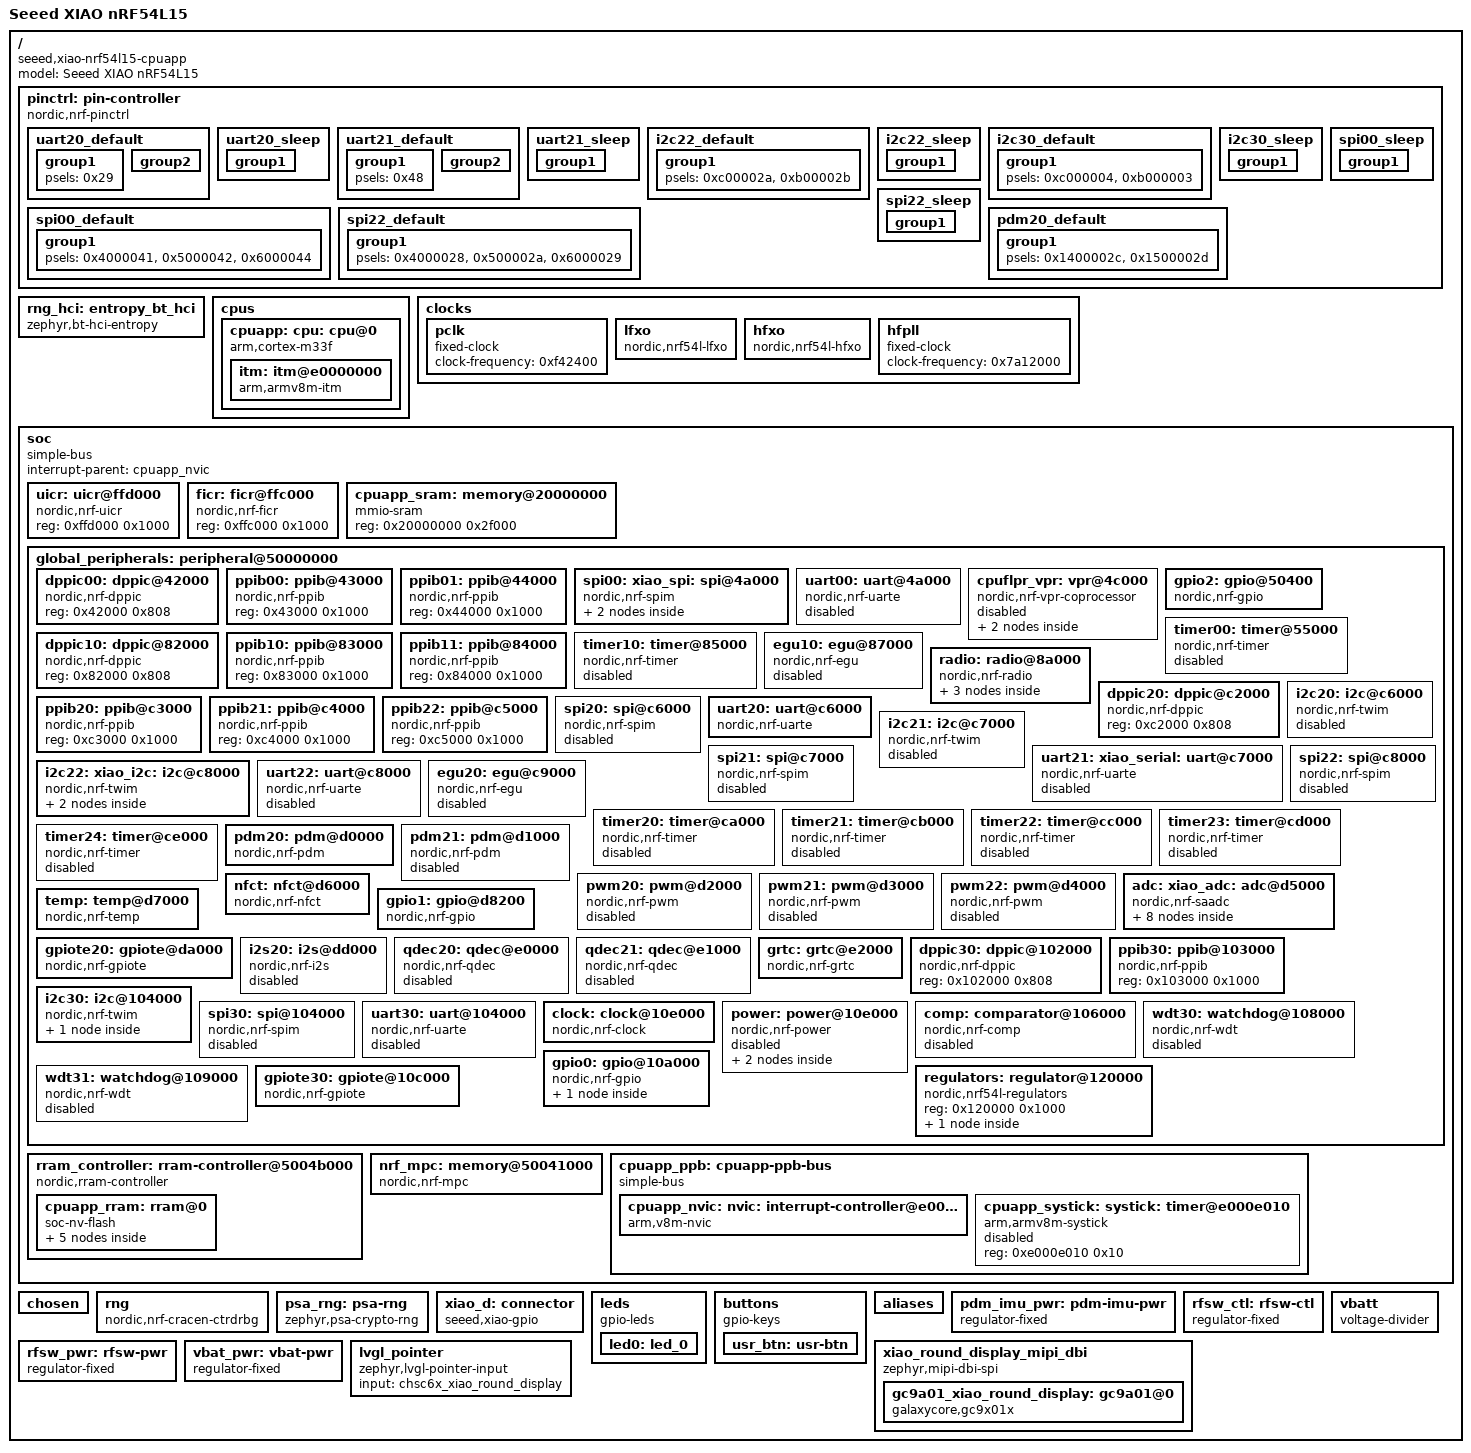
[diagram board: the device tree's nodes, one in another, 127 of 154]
/dts-v1/;

/* node '/' defined in zephyr\dts\vendor\nordic\nrf_common.dtsi:24 */
/ {
	#address-cells = < 0x1 >;                  /* in zephyr\dts\vendor\nordic\nrf54l_05_10_15.dtsi:19 */
	#size-cells = < 0x1 >;                     /* in zephyr\dts\vendor\nordic\nrf54l_05_10_15.dtsi:20 */
	model = "Seeed XIAO nRF54L15";             /* in zephyr\boards\arm\xiao_nrf54l15\xiao_nrf54l15_nrf54l15_cpuapp.dts:11 */
	compatible = "seeed,xiao-nrf54l15-cpuapp"; /* in zephyr\boards\arm\xiao_nrf54l15\xiao_nrf54l15_nrf54l15_cpuapp.dts:12 */

	/* node '/pin-controller' defined in zephyr\dts\vendor\nordic\nrf_common.dtsi:25 */
	pinctrl: pin-controller {
		compatible = "nordic,nrf-pinctrl"; /* in zephyr\dts\vendor\nordic\nrf_common.dtsi:30 */

		/* node '/pin-controller/uart20_default' defined in zephyr\boards\arm\xiao_nrf54l15\xiao_nrf54l15-pinctrl.dtsi:6 */
		uart20_default: uart20_default {
			phandle = < 0x8 >; /* in zephyr\boards\arm\xiao_nrf54l15\xiao_nrf54l15_common.dtsi:39 */

			/* node '/pin-controller/uart20_default/group1' defined in zephyr\boards\arm\xiao_nrf54l15\xiao_nrf54l15-pinctrl.dtsi:7 */
			group1 {
				psels = < 0x29 >; /* in zephyr\boards\arm\xiao_nrf54l15\xiao_nrf54l15-pinctrl.dtsi:8 */
			};

			/* node '/pin-controller/uart20_default/group2' defined in zephyr\boards\arm\xiao_nrf54l15\xiao_nrf54l15-pinctrl.dtsi:11 */
			group2 {
				psels = < 0x1000028 >; /* in zephyr\boards\arm\xiao_nrf54l15\xiao_nrf54l15-pinctrl.dtsi:12 */
				bias-pull-up;          /* in zephyr\boards\arm\xiao_nrf54l15\xiao_nrf54l15-pinctrl.dtsi:13 */
			};
		};

		/* node '/pin-controller/uart20_sleep' defined in zephyr\boards\arm\xiao_nrf54l15\xiao_nrf54l15-pinctrl.dtsi:17 */
		uart20_sleep: uart20_sleep {
			phandle = < 0x9 >; /* in zephyr\boards\arm\xiao_nrf54l15\xiao_nrf54l15_common.dtsi:40 */

			/* node '/pin-controller/uart20_sleep/group1' defined in zephyr\boards\arm\xiao_nrf54l15\xiao_nrf54l15-pinctrl.dtsi:18 */
			group1 {
				psels = < 0x29 >,
				        < 0x1000028 >; /* in zephyr\boards\arm\xiao_nrf54l15\xiao_nrf54l15-pinctrl.dtsi:19 */
				low-power-enable;      /* in zephyr\boards\arm\xiao_nrf54l15\xiao_nrf54l15-pinctrl.dtsi:21 */
			};
		};

		/* node '/pin-controller/uart21_default' defined in zephyr\boards\arm\xiao_nrf54l15\xiao_nrf54l15-pinctrl.dtsi:25 */
		uart21_default: uart21_default {
			phandle = < 0xa >; /* in zephyr\boards\arm\xiao_nrf54l15\xiao_nrf54l15_common.dtsi:46 */

			/* node '/pin-controller/uart21_default/group1' defined in zephyr\boards\arm\xiao_nrf54l15\xiao_nrf54l15-pinctrl.dtsi:26 */
			group1 {
				psels = < 0x48 >; /* in zephyr\boards\arm\xiao_nrf54l15\xiao_nrf54l15-pinctrl.dtsi:27 */
			};

			/* node '/pin-controller/uart21_default/group2' defined in zephyr\boards\arm\xiao_nrf54l15\xiao_nrf54l15-pinctrl.dtsi:30 */
			group2 {
				psels = < 0x1000047 >; /* in zephyr\boards\arm\xiao_nrf54l15\xiao_nrf54l15-pinctrl.dtsi:31 */
				bias-pull-up;          /* in zephyr\boards\arm\xiao_nrf54l15\xiao_nrf54l15-pinctrl.dtsi:32 */
			};
		};

		/* node '/pin-controller/uart21_sleep' defined in zephyr\boards\arm\xiao_nrf54l15\xiao_nrf54l15-pinctrl.dtsi:36 */
		uart21_sleep: uart21_sleep {
			phandle = < 0xb >; /* in zephyr\boards\arm\xiao_nrf54l15\xiao_nrf54l15_common.dtsi:47 */

			/* node '/pin-controller/uart21_sleep/group1' defined in zephyr\boards\arm\xiao_nrf54l15\xiao_nrf54l15-pinctrl.dtsi:37 */
			group1 {
				psels = < 0x48 >,
				        < 0x1000047 >; /* in zephyr\boards\arm\xiao_nrf54l15\xiao_nrf54l15-pinctrl.dtsi:38 */
				low-power-enable;      /* in zephyr\boards\arm\xiao_nrf54l15\xiao_nrf54l15-pinctrl.dtsi:40 */
			};
		};

		/* node '/pin-controller/i2c22_default' defined in zephyr\boards\arm\xiao_nrf54l15\xiao_nrf54l15-pinctrl.dtsi:44 */
		i2c22_default: i2c22_default {
			phandle = < 0xc >; /* in zephyr\boards\arm\xiao_nrf54l15\xiao_nrf54l15_common.dtsi:52 */

			/* node '/pin-controller/i2c22_default/group1' defined in zephyr\boards\arm\xiao_nrf54l15\xiao_nrf54l15-pinctrl.dtsi:45 */
			group1 {
				psels = < 0xc00002a >,
				        < 0xb00002b >; /* in zephyr\boards\arm\xiao_nrf54l15\xiao_nrf54l15-pinctrl.dtsi:46 */
			};
		};

		/* node '/pin-controller/i2c22_sleep' defined in zephyr\boards\arm\xiao_nrf54l15\xiao_nrf54l15-pinctrl.dtsi:51 */
		i2c22_sleep: i2c22_sleep {
			phandle = < 0xd >; /* in zephyr\boards\arm\xiao_nrf54l15\xiao_nrf54l15_common.dtsi:53 */

			/* node '/pin-controller/i2c22_sleep/group1' defined in zephyr\boards\arm\xiao_nrf54l15\xiao_nrf54l15-pinctrl.dtsi:52 */
			group1 {
				psels = < 0xc00002a >,
				        < 0xb00002b >; /* in zephyr\boards\arm\xiao_nrf54l15\xiao_nrf54l15-pinctrl.dtsi:53 */
				low-power-enable;      /* in zephyr\boards\arm\xiao_nrf54l15\xiao_nrf54l15-pinctrl.dtsi:55 */
			};
		};

		/* node '/pin-controller/i2c30_default' defined in zephyr\boards\arm\xiao_nrf54l15\xiao_nrf54l15-pinctrl.dtsi:59 */
		i2c30_default: i2c30_default {
			phandle = < 0x14 >; /* in zephyr\boards\arm\xiao_nrf54l15\xiao_nrf54l15_common.dtsi:59 */

			/* node '/pin-controller/i2c30_default/group1' defined in zephyr\boards\arm\xiao_nrf54l15\xiao_nrf54l15-pinctrl.dtsi:60 */
			group1 {
				psels = < 0xc000004 >,
				        < 0xb000003 >; /* in zephyr\boards\arm\xiao_nrf54l15\xiao_nrf54l15-pinctrl.dtsi:61 */
			};
		};

		/* node '/pin-controller/i2c30_sleep' defined in zephyr\boards\arm\xiao_nrf54l15\xiao_nrf54l15-pinctrl.dtsi:66 */
		i2c30_sleep: i2c30_sleep {
			phandle = < 0x15 >; /* in zephyr\boards\arm\xiao_nrf54l15\xiao_nrf54l15_common.dtsi:60 */

			/* node '/pin-controller/i2c30_sleep/group1' defined in zephyr\boards\arm\xiao_nrf54l15\xiao_nrf54l15-pinctrl.dtsi:67 */
			group1 {
				psels = < 0xc000004 >,
				        < 0xb000003 >; /* in zephyr\boards\arm\xiao_nrf54l15\xiao_nrf54l15-pinctrl.dtsi:68 */
				low-power-enable;      /* in zephyr\boards\arm\xiao_nrf54l15\xiao_nrf54l15-pinctrl.dtsi:70 */
			};
		};

		/* node '/pin-controller/spi00_default' defined in zephyr\boards\arm\xiao_nrf54l15\xiao_nrf54l15-pinctrl.dtsi:74 */
		spi00_default: spi00_default {
			phandle = < 0x3 >; /* in zephyr\boards\arm\xiao_nrf54l15\xiao_nrf54l15_common.dtsi:66 */

			/* node '/pin-controller/spi00_default/group1' defined in zephyr\boards\arm\xiao_nrf54l15\xiao_nrf54l15-pinctrl.dtsi:75 */
			group1 {
				psels = < 0x4000041 >,
				        < 0x5000042 >,
				        < 0x6000044 >; /* in zephyr\boards\arm\xiao_nrf54l15\xiao_nrf54l15-pinctrl.dtsi:76 */
			};
		};

		/* node '/pin-controller/spi00_sleep' defined in zephyr\boards\arm\xiao_nrf54l15\xiao_nrf54l15-pinctrl.dtsi:82 */
		spi00_sleep: spi00_sleep {
			phandle = < 0x4 >; /* in zephyr\boards\arm\xiao_nrf54l15\xiao_nrf54l15_common.dtsi:67 */

			/* node '/pin-controller/spi00_sleep/group1' defined in zephyr\boards\arm\xiao_nrf54l15\xiao_nrf54l15-pinctrl.dtsi:83 */
			group1 {
				psels = < 0x4000041 >,
				        < 0x5000042 >,
				        < 0x6000044 >; /* in zephyr\boards\arm\xiao_nrf54l15\xiao_nrf54l15-pinctrl.dtsi:84 */
				low-power-enable;      /* in zephyr\boards\arm\xiao_nrf54l15\xiao_nrf54l15-pinctrl.dtsi:87 */
			};
		};

		/* node '/pin-controller/spi22_default' defined in zephyr\boards\arm\xiao_nrf54l15\xiao_nrf54l15-pinctrl.dtsi:91 */
		spi22_default: spi22_default {
			phandle = < 0xe >; /* in zephyr\boards\arm\xiao_nrf54l15\xiao_nrf54l15_common.dtsi:72 */

			/* node '/pin-controller/spi22_default/group1' defined in zephyr\boards\arm\xiao_nrf54l15\xiao_nrf54l15-pinctrl.dtsi:92 */
			group1 {
				psels = < 0x4000028 >,
				        < 0x500002a >,
				        < 0x6000029 >; /* in zephyr\boards\arm\xiao_nrf54l15\xiao_nrf54l15-pinctrl.dtsi:93 */
			};
		};

		/* node '/pin-controller/spi22_sleep' defined in zephyr\boards\arm\xiao_nrf54l15\xiao_nrf54l15-pinctrl.dtsi:99 */
		spi22_sleep: spi22_sleep {
			phandle = < 0xf >; /* in zephyr\boards\arm\xiao_nrf54l15\xiao_nrf54l15_common.dtsi:73 */

			/* node '/pin-controller/spi22_sleep/group1' defined in zephyr\boards\arm\xiao_nrf54l15\xiao_nrf54l15-pinctrl.dtsi:100 */
			group1 {
				psels = < 0x4000028 >,
				        < 0x500002a >,
				        < 0x6000029 >; /* in zephyr\boards\arm\xiao_nrf54l15\xiao_nrf54l15-pinctrl.dtsi:101 */
				low-power-enable;      /* in zephyr\boards\arm\xiao_nrf54l15\xiao_nrf54l15-pinctrl.dtsi:104 */
			};
		};

		/* node '/pin-controller/pdm20_default' defined in zephyr\boards\arm\xiao_nrf54l15\xiao_nrf54l15-pinctrl.dtsi:108 */
		pdm20_default: pdm20_default {
			phandle = < 0x10 >; /* in zephyr\boards\arm\xiao_nrf54l15\xiao_nrf54l15_common.dtsi:78 */

			/* node '/pin-controller/pdm20_default/group1' defined in zephyr\boards\arm\xiao_nrf54l15\xiao_nrf54l15-pinctrl.dtsi:109 */
			group1 {
				psels = < 0x1400002c >,
				        < 0x1500002d >; /* in zephyr\boards\arm\xiao_nrf54l15\xiao_nrf54l15-pinctrl.dtsi:110 */
			};
		};
	};

	/* node '/entropy_bt_hci' defined in zephyr\dts\vendor\nordic\nrf_common.dtsi:33 */
	rng_hci: entropy_bt_hci {
		compatible = "zephyr,bt-hci-entropy"; /* in zephyr\dts\vendor\nordic\nrf_common.dtsi:34 */
		status = "okay";                      /* in zephyr\dts\vendor\nordic\nrf_common.dtsi:35 */
	};

	/* node '/cpus' defined in zephyr\dts\vendor\nordic\nrf54l_05_10_15.dtsi:22 */
	cpus {
		#address-cells = < 0x1 >; /* in zephyr\dts\vendor\nordic\nrf54l_05_10_15.dtsi:23 */
		#size-cells = < 0x0 >;    /* in zephyr\dts\vendor\nordic\nrf54l_05_10_15.dtsi:24 */

		/* node '/cpus/cpu@0' defined in zephyr\dts\vendor\nordic\nrf54l_05_10_15.dtsi:26 */
		cpuapp: cpu: cpu@0 {
			compatible = "arm,cortex-m33f"; /* in zephyr\dts\vendor\nordic\nrf54l_05_10_15.dtsi:27 */
			reg = < 0x0 >;                  /* in zephyr\dts\vendor\nordic\nrf54l_05_10_15.dtsi:28 */
			device_type = "cpu";            /* in zephyr\dts\vendor\nordic\nrf54l_05_10_15.dtsi:29 */
			clocks = < &hfpll >;            /* in zephyr\dts\vendor\nordic\nrf54l_05_10_15.dtsi:30 */
			#address-cells = < 0x1 >;       /* in zephyr\dts\vendor\nordic\nrf54l_05_10_15.dtsi:31 */
			#size-cells = < 0x1 >;          /* in zephyr\dts\vendor\nordic\nrf54l_05_10_15.dtsi:32 */

			/* node '/cpus/cpu@0/itm@e0000000' defined in zephyr\dts\vendor\nordic\nrf54l_05_10_15.dtsi:34 */
			itm: itm@e0000000 {
				compatible = "arm,armv8m-itm";     /* in zephyr\dts\vendor\nordic\nrf54l_05_10_15.dtsi:35 */
				reg = < 0xe0000000 0x1000 >;       /* in zephyr\dts\vendor\nordic\nrf54l_05_10_15.dtsi:36 */
				swo-ref-frequency = < 0x7a12000 >; /* in zephyr\dts\vendor\nordic\nrf54l_05_10_15.dtsi:37 */
			};
		};
	};

	/* node '/clocks' defined in zephyr\dts\vendor\nordic\nrf54l_05_10_15.dtsi:51 */
	clocks {

		/* node '/clocks/pclk' defined in zephyr\dts\vendor\nordic\nrf54l_05_10_15.dtsi:52 */
		pclk: pclk {
			compatible = "fixed-clock";     /* in zephyr\dts\vendor\nordic\nrf54l_05_10_15.dtsi:53 */
			#clock-cells = < 0x0 >;         /* in zephyr\dts\vendor\nordic\nrf54l_05_10_15.dtsi:54 */
			clock-frequency = < 0xf42400 >; /* in zephyr\dts\vendor\nordic\nrf54l_05_10_15.dtsi:55 */
			phandle = < 0x13 >;             /* in zephyr\dts\vendor\nordic\nrf54l_05_10_15.dtsi:579 */
		};

		/* node '/clocks/lfxo' defined in zephyr\dts\vendor\nordic\nrf54l_05_10_15.dtsi:58 */
		lfxo: lfxo {
			compatible = "nordic,nrf54l-lfxo";        /* in zephyr\dts\vendor\nordic\nrf54l_05_10_15.dtsi:59 */
			#clock-cells = < 0x0 >;                   /* in zephyr\dts\vendor\nordic\nrf54l_05_10_15.dtsi:60 */
			clock-frequency = < 0x8000 >;             /* in zephyr\dts\vendor\nordic\nrf54l_05_10_15.dtsi:61 */
			load-capacitors = "internal";             /* in zephyr\boards\arm\xiao_nrf54l15\xiao_nrf54l15_nrf54l15_cpuapp.dts:147 */
			load-capacitance-femtofarad = < 0x3e80 >; /* in zephyr\boards\arm\xiao_nrf54l15\xiao_nrf54l15_nrf54l15_cpuapp.dts:148 */
			status = "okay";                          /* in zephyr\boards\arm\xiao_nrf54l15\xiao_nrf54l15_nrf54l15_cpuapp.dts:149 */
			phandle = < 0x12 >;                       /* in zephyr\dts\vendor\nordic\nrf54l_05_10_15.dtsi:579 */
		};

		/* node '/clocks/hfxo' defined in zephyr\dts\vendor\nordic\nrf54l_05_10_15.dtsi:64 */
		hfxo: hfxo {
			compatible = "nordic,nrf54l-hfxo";        /* in zephyr\dts\vendor\nordic\nrf54l_05_10_15.dtsi:65 */
			#clock-cells = < 0x0 >;                   /* in zephyr\dts\vendor\nordic\nrf54l_05_10_15.dtsi:66 */
			clock-frequency = < 0x1e84800 >;          /* in zephyr\dts\vendor\nordic\nrf54l_05_10_15.dtsi:67 */
			startup-time-us = < 0x672 >;              /* in zephyr\dts\vendor\nordic\nrf54l_05_10_15.dtsi:68 */
			load-capacitors = "internal";             /* in zephyr\boards\arm\xiao_nrf54l15\xiao_nrf54l15_nrf54l15_cpuapp.dts:153 */
			load-capacitance-femtofarad = < 0x3e80 >; /* in zephyr\boards\arm\xiao_nrf54l15\xiao_nrf54l15_nrf54l15_cpuapp.dts:154 */
			status = "okay";                          /* in zephyr\boards\arm\xiao_nrf54l15\xiao_nrf54l15_nrf54l15_cpuapp.dts:155 */
			phandle = < 0x6 >;                        /* in zephyr\dts\vendor\nordic\nrf54l_05_10_15.dtsi:226 */
		};

		/* node '/clocks/hfpll' defined in zephyr\dts\vendor\nordic\nrf54l_05_10_15.dtsi:71 */
		hfpll: hfpll {
			compatible = "fixed-clock";      /* in zephyr\dts\vendor\nordic\nrf54l_05_10_15.dtsi:72 */
			#clock-cells = < 0x0 >;          /* in zephyr\dts\vendor\nordic\nrf54l_05_10_15.dtsi:73 */
			clock-frequency = < 0x7a12000 >; /* in zephyr\dts\vendor\nordic\nrf54l_05_10_15.dtsi:74 */
			phandle = < 0x1 >;               /* in zephyr\dts\vendor\nordic\nrf54l_05_10_15.dtsi:30 */
		};
	};

	/* node '/soc' defined in zephyr\dts\vendor\nordic\nrf54l_05_10_15.dtsi:78 */
	soc {
		#address-cells = < 0x1 >;            /* in zephyr\dts\vendor\nordic\nrf54l_05_10_15.dtsi:79 */
		#size-cells = < 0x1 >;               /* in zephyr\dts\vendor\nordic\nrf54l_05_10_15.dtsi:80 */
		compatible = "simple-bus";           /* in zephyr\dts\arm\nordic\nrf54l_05_10_15_cpuapp.dtsi:23 */
		interrupt-parent = < &cpuapp_nvic >; /* in zephyr\dts\arm\nordic\nrf54l_05_10_15_cpuapp.dtsi:24 */
		ranges;                              /* in zephyr\dts\arm\nordic\nrf54l_05_10_15_cpuapp.dtsi:25 */

		/* node '/soc/uicr@ffd000' defined in zephyr\dts\vendor\nordic\nrf54l_05_10_15.dtsi:85 */
		uicr: uicr@ffd000 {
			compatible = "nordic,nrf-uicr"; /* in zephyr\dts\vendor\nordic\nrf54l_05_10_15.dtsi:86 */
			reg = < 0xffd000 0x1000 >;      /* in zephyr\dts\vendor\nordic\nrf54l_05_10_15.dtsi:87 */
		};

		/* node '/soc/ficr@ffc000' defined in zephyr\dts\vendor\nordic\nrf54l_05_10_15.dtsi:90 */
		ficr: ficr@ffc000 {
			compatible = "nordic,nrf-ficr"; /* in zephyr\dts\vendor\nordic\nrf54l_05_10_15.dtsi:91 */
			reg = < 0xffc000 0x1000 >;      /* in zephyr\dts\vendor\nordic\nrf54l_05_10_15.dtsi:92 */
			#nordic,ficr-cells = < 0x1 >;   /* in zephyr\dts\vendor\nordic\nrf54l_05_10_15.dtsi:93 */
		};

		/* node '/soc/memory@20000000' defined in zephyr\dts\vendor\nordic\nrf54l_05_10_15.dtsi:96 */
		cpuapp_sram: memory@20000000 {
			compatible = "mmio-sram";            /* in zephyr\dts\vendor\nordic\nrf54l_05_10_15.dtsi:97 */
			#address-cells = < 0x1 >;            /* in zephyr\dts\vendor\nordic\nrf54l_05_10_15.dtsi:98 */
			#size-cells = < 0x1 >;               /* in zephyr\dts\vendor\nordic\nrf54l_05_10_15.dtsi:99 */
			reg = < 0x20000000 0x2f000 >;        /* in zephyr\dts\vendor\nordic\nrf54l15.dtsi:10 */
			ranges = < 0x0 0x20000000 0x2f000 >; /* in zephyr\dts\vendor\nordic\nrf54l15.dtsi:11 */
			status = "okay";                     /* in zephyr\boards\arm\xiao_nrf54l15\xiao_nrf54l15_nrf54l15_cpuapp.dts:60 */
		};

		/* node '/soc/peripheral@50000000' defined in zephyr\dts\vendor\nordic\nrf54l_05_10_15.dtsi:108 */
		global_peripherals: peripheral@50000000 {
			#address-cells = < 0x1 >;               /* in zephyr\dts\vendor\nordic\nrf54l_05_10_15.dtsi:109 */
			#size-cells = < 0x1 >;                  /* in zephyr\dts\vendor\nordic\nrf54l_05_10_15.dtsi:110 */
			ranges = < 0x0 0x50000000 0x10000000 >; /* in zephyr\dts\vendor\nordic\nrf54l_05_10_15.dtsi:111 */

			/* node '/soc/peripheral@50000000/dppic@42000' defined in zephyr\dts\vendor\nordic\nrf54l_05_10_15.dtsi:114 */
			dppic00: dppic@42000 {
				compatible = "nordic,nrf-dppic"; /* in zephyr\dts\vendor\nordic\nrf54l_05_10_15.dtsi:115 */
				reg = < 0x42000 0x808 >;         /* in zephyr\dts\vendor\nordic\nrf54l_05_10_15.dtsi:116 */
				status = "okay";                 /* in zephyr\dts\arm\nordic\nrf54l_05_10_15_cpuapp.dtsi:96 */
			};

			/* node '/soc/peripheral@50000000/ppib@43000' defined in zephyr\dts\vendor\nordic\nrf54l_05_10_15.dtsi:120 */
			ppib00: ppib@43000 {
				compatible = "nordic,nrf-ppib"; /* in zephyr\dts\vendor\nordic\nrf54l_05_10_15.dtsi:121 */
				reg = < 0x43000 0x1000 >;       /* in zephyr\dts\vendor\nordic\nrf54l_05_10_15.dtsi:122 */
				status = "okay";                /* in zephyr\dts\arm\nordic\nrf54l_05_10_15_cpuapp.dtsi:112 */
			};

			/* node '/soc/peripheral@50000000/ppib@44000' defined in zephyr\dts\vendor\nordic\nrf54l_05_10_15.dtsi:126 */
			ppib01: ppib@44000 {
				compatible = "nordic,nrf-ppib"; /* in zephyr\dts\vendor\nordic\nrf54l_05_10_15.dtsi:127 */
				reg = < 0x44000 0x1000 >;       /* in zephyr\dts\vendor\nordic\nrf54l_05_10_15.dtsi:128 */
				status = "okay";                /* in zephyr\dts\arm\nordic\nrf54l_05_10_15_cpuapp.dtsi:116 */
			};

			/* node '/soc/peripheral@50000000/spi@4a000' defined in zephyr\dts\vendor\nordic\nrf54l_05_10_15.dtsi:132 */
			spi00: xiao_spi: spi@4a000 {
				compatible = "nordic,nrf-spim"; /* in zephyr\dts\vendor\nordic\nrf54l_05_10_15.dtsi:139 */
				#address-cells = < 0x1 >;       /* in zephyr\dts\vendor\nordic\nrf54l_05_10_15.dtsi:140 */
				#size-cells = < 0x0 >;          /* in zephyr\dts\vendor\nordic\nrf54l_05_10_15.dtsi:141 */
				reg = < 0x4a000 0x1000 >;       /* in zephyr\dts\vendor\nordic\nrf54l_05_10_15.dtsi:142 */
				interrupts = < 0x4a 0x1 >;      /* in zephyr\dts\vendor\nordic\nrf54l_05_10_15.dtsi:143 */
				max-frequency = < 0x1e84800 >;  /* in zephyr\dts\vendor\nordic\nrf54l_05_10_15.dtsi:144 */
				easydma-maxcnt-bits = < 0x10 >; /* in zephyr\dts\vendor\nordic\nrf54l_05_10_15.dtsi:145 */
				rx-delay-supported;             /* in zephyr\dts\vendor\nordic\nrf54l_05_10_15.dtsi:146 */
				rx-delay = < 0x1 >;             /* in zephyr\dts\vendor\nordic\nrf54l_05_10_15.dtsi:147 */
				status = "okay";                /* in zephyr\boards\shields\seeed_xiao_round_display\seeed_xiao_round_display.overlay:83 */
				pinctrl-0 = < &spi00_default >; /* in zephyr\boards\arm\xiao_nrf54l15\xiao_nrf54l15_common.dtsi:66 */
				pinctrl-1 = < &spi00_sleep >;   /* in zephyr\boards\arm\xiao_nrf54l15\xiao_nrf54l15_common.dtsi:67 */
				pinctrl-names = "default",
				                "sleep";        /* in zephyr\boards\arm\xiao_nrf54l15\xiao_nrf54l15_common.dtsi:68 */
				cs-gpios = < &xiao_d 0x1 0x1 >,
				           < &xiao_d 0x2 0x1 >; /* in zephyr\boards\shields\seeed_xiao_round_display\seeed_xiao_round_display.overlay:84 */
				phandle = < 0x1b >;             /* in zephyr\boards\shields\seeed_xiao_round_display\seeed_xiao_round_display.overlay:34 */

				/* node '/soc/peripheral@50000000/spi@4a000/sdhc@1' defined in zephyr\boards\shields\seeed_xiao_round_display\seeed_xiao_round_display.overlay:86 */
				sdhc_xiao_round_display: sdhc@1 {
					compatible = "zephyr,sdhc-spi-slot"; /* in zephyr\boards\shields\seeed_xiao_round_display\seeed_xiao_round_display.overlay:87 */
					reg = < 0x1 >;                       /* in zephyr\boards\shields\seeed_xiao_round_display\seeed_xiao_round_display.overlay:88 */
					status = "okay";                     /* in zephyr\boards\shields\seeed_xiao_round_display\seeed_xiao_round_display.overlay:89 */
					spi-max-frequency = < 0x16e3600 >;   /* in zephyr\boards\shields\seeed_xiao_round_display\seeed_xiao_round_display.overlay:95 */

					/* node '/soc/peripheral@50000000/spi@4a000/sdhc@1/mmc' defined in zephyr\boards\shields\seeed_xiao_round_display\seeed_xiao_round_display.overlay:90 */
					mmc {
						compatible = "zephyr,sdmmc-disk"; /* in zephyr\boards\shields\seeed_xiao_round_display\seeed_xiao_round_display.overlay:91 */
						disk-name = "SD";                 /* in zephyr\boards\shields\seeed_xiao_round_display\seeed_xiao_round_display.overlay:92 */
						status = "okay";                  /* in zephyr\boards\shields\seeed_xiao_round_display\seeed_xiao_round_display.overlay:93 */
					};
				};
			};

			/* node '/soc/peripheral@50000000/uart@4a000' defined in zephyr\dts\vendor\nordic\nrf54l_05_10_15.dtsi:151 */
			uart00: uart@4a000 {
				compatible = "nordic,nrf-uarte"; /* in zephyr\dts\vendor\nordic\nrf54l_05_10_15.dtsi:152 */
				reg = < 0x4a000 0x1000 >;        /* in zephyr\dts\vendor\nordic\nrf54l_05_10_15.dtsi:153 */
				interrupts = < 0x4a 0x1 >;       /* in zephyr\dts\vendor\nordic\nrf54l_05_10_15.dtsi:154 */
				clocks = < &hfpll >;             /* in zephyr\dts\vendor\nordic\nrf54l_05_10_15.dtsi:155 */
				status = "disabled";             /* in zephyr\dts\vendor\nordic\nrf54l_05_10_15.dtsi:156 */
				endtx-stoptx-supported;          /* in zephyr\dts\vendor\nordic\nrf54l_05_10_15.dtsi:157 */
				frame-timeout-supported;         /* in zephyr\dts\vendor\nordic\nrf54l_05_10_15.dtsi:158 */
			};

			/* node '/soc/peripheral@50000000/vpr@4c000' defined in zephyr\dts\vendor\nordic\nrf54l_05_10_15.dtsi:161 */
			cpuflpr_vpr: vpr@4c000 {
				compatible = "nordic,nrf-vpr-coprocessor"; /* in zephyr\dts\vendor\nordic\nrf54l_05_10_15.dtsi:162 */
				reg = < 0x4c000 0x1000 >;                  /* in zephyr\dts\vendor\nordic\nrf54l_05_10_15.dtsi:163 */
				ranges = < 0x0 0x4c000 0x1000 >;           /* in zephyr\dts\vendor\nordic\nrf54l_05_10_15.dtsi:164 */
				#address-cells = < 0x1 >;                  /* in zephyr\dts\vendor\nordic\nrf54l_05_10_15.dtsi:165 */
				#size-cells = < 0x1 >;                     /* in zephyr\dts\vendor\nordic\nrf54l_05_10_15.dtsi:166 */
				status = "disabled";                       /* in zephyr\dts\vendor\nordic\nrf54l_05_10_15.dtsi:167 */
				enable-secure;                             /* in zephyr\dts\vendor\nordic\nrf54l_05_10_15.dtsi:168 */

				/* node '/soc/peripheral@50000000/vpr@4c000/mailbox@1' defined in zephyr\dts\arm\nordic\nrf54l_05_10_15_cpuapp.dtsi:45 */
				cpuapp_vevif_rx: mailbox@1 {
					compatible = "nordic,nrf-vevif-event-rx"; /* in zephyr\dts\arm\nordic\nrf54l_05_10_15_cpuapp.dtsi:46 */
					reg = < 0x1 0x1000 >;                     /* in zephyr\dts\arm\nordic\nrf54l_05_10_15_cpuapp.dtsi:47 */
					status = "disabled";                      /* in zephyr\dts\arm\nordic\nrf54l_05_10_15_cpuapp.dtsi:48 */
					interrupts = < 0x4c 0x1 >;                /* in zephyr\dts\arm\nordic\nrf54l_05_10_15_cpuapp.dtsi:49 */
					#mbox-cells = < 0x1 >;                    /* in zephyr\dts\arm\nordic\nrf54l_05_10_15_cpuapp.dtsi:50 */
					nordic,events = < 0x1 >;                  /* in zephyr\dts\arm\nordic\nrf54l_05_10_15_cpuapp.dtsi:51 */
					nordic,events-mask = < 0x100000 >;        /* in zephyr\dts\arm\nordic\nrf54l_05_10_15_cpuapp.dtsi:52 */
				};

				/* node '/soc/peripheral@50000000/vpr@4c000/mailbox@0' defined in zephyr\dts\arm\nordic\nrf54l_05_10_15_cpuapp.dtsi:55 */
				cpuapp_vevif_tx: mailbox@0 {
					compatible = "nordic,nrf-vevif-task-tx"; /* in zephyr\dts\arm\nordic\nrf54l_05_10_15_cpuapp.dtsi:56 */
					reg = < 0x0 0x1000 >;                    /* in zephyr\dts\arm\nordic\nrf54l_05_10_15_cpuapp.dtsi:57 */
					#mbox-cells = < 0x1 >;                   /* in zephyr\dts\arm\nordic\nrf54l_05_10_15_cpuapp.dtsi:58 */
					nordic,tasks = < 0x7 >;                  /* in zephyr\dts\arm\nordic\nrf54l_05_10_15_cpuapp.dtsi:59 */
					nordic,tasks-mask = < 0x7f0000 >;        /* in zephyr\dts\arm\nordic\nrf54l_05_10_15_cpuapp.dtsi:60 */
					status = "disabled";                     /* in zephyr\dts\arm\nordic\nrf54l_05_10_15_cpuapp.dtsi:61 */
				};
			};

			/* node '/soc/peripheral@50000000/gpio@50400' defined in zephyr\dts\vendor\nordic\nrf54l_05_10_15.dtsi:180 */
			gpio2: gpio@50400 {
				compatible = "nordic,nrf-gpio"; /* in zephyr\dts\vendor\nordic\nrf54l_05_10_15.dtsi:181 */
				gpio-controller;                /* in zephyr\dts\vendor\nordic\nrf54l_05_10_15.dtsi:182 */
				reg = < 0x50400 0x300 >;        /* in zephyr\dts\vendor\nordic\nrf54l_05_10_15.dtsi:183 */
				#gpio-cells = < 0x2 >;          /* in zephyr\dts\vendor\nordic\nrf54l_05_10_15.dtsi:184 */
				ngpios = < 0xb >;               /* in zephyr\dts\vendor\nordic\nrf54l_05_10_15.dtsi:185 */
				status = "okay";                /* in zephyr\boards\arm\xiao_nrf54l15\xiao_nrf54l15_nrf54l15_cpuapp.dts:126 */
				port = < 0x2 >;                 /* in zephyr\dts\vendor\nordic\nrf54l_05_10_15.dtsi:187 */
				phandle = < 0x18 >;             /* in zephyr\boards\arm\xiao_nrf54l15\seeed_xiao_connector.dtsi:11 */
			};

			/* node '/soc/peripheral@50000000/timer@55000' defined in zephyr\dts\vendor\nordic\nrf54l_05_10_15.dtsi:190 */
			timer00: timer@55000 {
				compatible = "nordic,nrf-timer"; /* in zephyr\dts\vendor\nordic\nrf54l_05_10_15.dtsi:191 */
				status = "disabled";             /* in zephyr\dts\vendor\nordic\nrf54l_05_10_15.dtsi:192 */
				reg = < 0x55000 0x1000 >;        /* in zephyr\dts\vendor\nordic\nrf54l_05_10_15.dtsi:193 */
				cc-num = < 0x6 >;                /* in zephyr\dts\vendor\nordic\nrf54l_05_10_15.dtsi:194 */
				max-bit-width = < 0x20 >;        /* in zephyr\dts\vendor\nordic\nrf54l_05_10_15.dtsi:195 */
				interrupts = < 0x55 0x1 >;       /* in zephyr\dts\vendor\nordic\nrf54l_05_10_15.dtsi:196 */
				clocks = < &hfpll >;             /* in zephyr\dts\vendor\nordic\nrf54l_05_10_15.dtsi:197 */
				prescaler = < 0x0 >;             /* in zephyr\dts\vendor\nordic\nrf54l_05_10_15.dtsi:198 */
			};

			/* node '/soc/peripheral@50000000/dppic@82000' defined in zephyr\dts\vendor\nordic\nrf54l_05_10_15.dtsi:201 */
			dppic10: dppic@82000 {
				compatible = "nordic,nrf-dppic"; /* in zephyr\dts\vendor\nordic\nrf54l_05_10_15.dtsi:202 */
				reg = < 0x82000 0x808 >;         /* in zephyr\dts\vendor\nordic\nrf54l_05_10_15.dtsi:203 */
				status = "okay";                 /* in zephyr\dts\arm\nordic\nrf54l_05_10_15_cpuapp.dtsi:100 */
			};

			/* node '/soc/peripheral@50000000/ppib@83000' defined in zephyr\dts\vendor\nordic\nrf54l_05_10_15.dtsi:207 */
			ppib10: ppib@83000 {
				compatible = "nordic,nrf-ppib"; /* in zephyr\dts\vendor\nordic\nrf54l_05_10_15.dtsi:208 */
				reg = < 0x83000 0x1000 >;       /* in zephyr\dts\vendor\nordic\nrf54l_05_10_15.dtsi:209 */
				status = "okay";                /* in zephyr\dts\arm\nordic\nrf54l_05_10_15_cpuapp.dtsi:120 */
			};

			/* node '/soc/peripheral@50000000/ppib@84000' defined in zephyr\dts\vendor\nordic\nrf54l_05_10_15.dtsi:213 */
			ppib11: ppib@84000 {
				compatible = "nordic,nrf-ppib"; /* in zephyr\dts\vendor\nordic\nrf54l_05_10_15.dtsi:214 */
				reg = < 0x84000 0x1000 >;       /* in zephyr\dts\vendor\nordic\nrf54l_05_10_15.dtsi:215 */
				status = "okay";                /* in zephyr\dts\arm\nordic\nrf54l_05_10_15_cpuapp.dtsi:124 */
			};

			/* node '/soc/peripheral@50000000/timer@85000' defined in zephyr\dts\vendor\nordic\nrf54l_05_10_15.dtsi:219 */
			timer10: timer@85000 {
				compatible = "nordic,nrf-timer"; /* in zephyr\dts\vendor\nordic\nrf54l_05_10_15.dtsi:220 */
				status = "disabled";             /* in zephyr\dts\vendor\nordic\nrf54l_05_10_15.dtsi:221 */
				reg = < 0x85000 0x1000 >;        /* in zephyr\dts\vendor\nordic\nrf54l_05_10_15.dtsi:222 */
				cc-num = < 0x8 >;                /* in zephyr\dts\vendor\nordic\nrf54l_05_10_15.dtsi:223 */
				max-bit-width = < 0x20 >;        /* in zephyr\dts\vendor\nordic\nrf54l_05_10_15.dtsi:224 */
				interrupts = < 0x85 0x1 >;       /* in zephyr\dts\vendor\nordic\nrf54l_05_10_15.dtsi:225 */
				clocks = < &hfxo >;              /* in zephyr\dts\vendor\nordic\nrf54l_05_10_15.dtsi:226 */
				prescaler = < 0x0 >;             /* in zephyr\dts\vendor\nordic\nrf54l_05_10_15.dtsi:227 */
			};

			/* node '/soc/peripheral@50000000/egu@87000' defined in zephyr\dts\vendor\nordic\nrf54l_05_10_15.dtsi:230 */
			egu10: egu@87000 {
				compatible = "nordic,nrf-egu"; /* in zephyr\dts\vendor\nordic\nrf54l_05_10_15.dtsi:231 */
				reg = < 0x87000 0x1000 >;      /* in zephyr\dts\vendor\nordic\nrf54l_05_10_15.dtsi:232 */
				interrupts = < 0x87 0x1 >;     /* in zephyr\dts\vendor\nordic\nrf54l_05_10_15.dtsi:233 */
				status = "disabled";           /* in zephyr\dts\vendor\nordic\nrf54l_05_10_15.dtsi:234 */
			};

			/* node '/soc/peripheral@50000000/radio@8a000' defined in zephyr\dts\vendor\nordic\nrf54l_05_10_15.dtsi:237 */
			radio: radio@8a000 {
				compatible = "nordic,nrf-radio"; /* in zephyr\dts\vendor\nordic\nrf54l_05_10_15.dtsi:238 */
				reg = < 0x8a000 0x1000 >;        /* in zephyr\dts\vendor\nordic\nrf54l_05_10_15.dtsi:239 */
				interrupts = < 0x8a 0x1 >;       /* in zephyr\dts\vendor\nordic\nrf54l_05_10_15.dtsi:240 */
				status = "okay";                 /* in zephyr\boards\arm\xiao_nrf54l15\xiao_nrf54l15_nrf54l15_cpuapp.dts:168 */
				dfe-supported;                   /* in zephyr\dts\vendor\nordic\nrf54l_05_10_15.dtsi:242 */
				ieee802154-supported;            /* in zephyr\dts\vendor\nordic\nrf54l_05_10_15.dtsi:243 */
				ble-2mbps-supported;             /* in zephyr\dts\vendor\nordic\nrf54l_05_10_15.dtsi:244 */
				ble-coded-phy-supported;         /* in zephyr\dts\vendor\nordic\nrf54l_05_10_15.dtsi:245 */
				cs-supported;                    /* in zephyr\dts\vendor\nordic\nrf54l_05_10_15.dtsi:246 */

				/* node '/soc/peripheral@50000000/radio@8a000/ieee802154' defined in zephyr\dts\vendor\nordic\nrf54l_05_10_15.dtsi:248 */
				ieee802154: ieee802154 {
					compatible = "nordic,nrf-ieee802154"; /* in zephyr\dts\vendor\nordic\nrf54l_05_10_15.dtsi:249 */
					status = "okay";                      /* in zephyr\boards\arm\xiao_nrf54l15\xiao_nrf54l15_nrf54l15_cpuapp.dts:160 */
				};

				/* node '/soc/peripheral@50000000/radio@8a000/bt_hci_sdc' defined in zephyr\dts\vendor\nordic\nrf54l_05_10_15.dtsi:253 */
				bt_hci_sdc: bt_hci_sdc {
					compatible = "zephyr,bt-hci-sdc"; /* in zephyr\dts\arm\nordic\nrf54l_05_10_15_cpuapp.dtsi:41 */
					status = "okay";                  /* in zephyr\dts\arm\nordic\nrf54l_05_10_15_cpuapp.dtsi:40 */
				};

				/* node '/soc/peripheral@50000000/radio@8a000/bt_hci_controller' defined in zephyr\dts\vendor\nordic\nrf54l_05_10_15.dtsi:258 */
				bt_hci_controller: bt_hci_controller {
					compatible = "zephyr,bt-hci-ll-sw-split"; /* in zephyr\dts\vendor\nordic\nrf54l_05_10_15.dtsi:259 */
					status = "disabled";                      /* in zephyr\dts\vendor\nordic\nrf54l_05_10_15.dtsi:260 */
				};
			};

			/* node '/soc/peripheral@50000000/dppic@c2000' defined in zephyr\dts\vendor\nordic\nrf54l_05_10_15.dtsi:264 */
			dppic20: dppic@c2000 {
				compatible = "nordic,nrf-dppic"; /* in zephyr\dts\vendor\nordic\nrf54l_05_10_15.dtsi:265 */
				reg = < 0xc2000 0x808 >;         /* in zephyr\dts\vendor\nordic\nrf54l_05_10_15.dtsi:266 */
				status = "okay";                 /* in zephyr\dts\arm\nordic\nrf54l_05_10_15_cpuapp.dtsi:104 */
			};

			/* node '/soc/peripheral@50000000/ppib@c3000' defined in zephyr\dts\vendor\nordic\nrf54l_05_10_15.dtsi:270 */
			ppib20: ppib@c3000 {
				compatible = "nordic,nrf-ppib"; /* in zephyr\dts\vendor\nordic\nrf54l_05_10_15.dtsi:271 */
				reg = < 0xc3000 0x1000 >;       /* in zephyr\dts\vendor\nordic\nrf54l_05_10_15.dtsi:272 */
				status = "okay";                /* in zephyr\dts\arm\nordic\nrf54l_05_10_15_cpuapp.dtsi:128 */
			};

			/* node '/soc/peripheral@50000000/ppib@c4000' defined in zephyr\dts\vendor\nordic\nrf54l_05_10_15.dtsi:276 */
			ppib21: ppib@c4000 {
				compatible = "nordic,nrf-ppib"; /* in zephyr\dts\vendor\nordic\nrf54l_05_10_15.dtsi:277 */
				reg = < 0xc4000 0x1000 >;       /* in zephyr\dts\vendor\nordic\nrf54l_05_10_15.dtsi:278 */
				status = "okay";                /* in zephyr\dts\arm\nordic\nrf54l_05_10_15_cpuapp.dtsi:132 */
			};

			/* node '/soc/peripheral@50000000/ppib@c5000' defined in zephyr\dts\vendor\nordic\nrf54l_05_10_15.dtsi:282 */
			ppib22: ppib@c5000 {
				compatible = "nordic,nrf-ppib"; /* in zephyr\dts\vendor\nordic\nrf54l_05_10_15.dtsi:283 */
				reg = < 0xc5000 0x1000 >;       /* in zephyr\dts\vendor\nordic\nrf54l_05_10_15.dtsi:284 */
				status = "okay";                /* in zephyr\dts\arm\nordic\nrf54l_05_10_15_cpuapp.dtsi:136 */
			};

			/* node '/soc/peripheral@50000000/i2c@c6000' defined in zephyr\dts\vendor\nordic\nrf54l_05_10_15.dtsi:288 */
			i2c20: i2c@c6000 {
				compatible = "nordic,nrf-twim"; /* in zephyr\dts\vendor\nordic\nrf54l_05_10_15.dtsi:289 */
				#address-cells = < 0x1 >;       /* in zephyr\dts\vendor\nordic\nrf54l_05_10_15.dtsi:290 */
				#size-cells = < 0x0 >;          /* in zephyr\dts\vendor\nordic\nrf54l_05_10_15.dtsi:291 */
				reg = < 0xc6000 0x1000 >;       /* in zephyr\dts\vendor\nordic\nrf54l_05_10_15.dtsi:292 */
				interrupts = < 0xc6 0x1 >;      /* in zephyr\dts\vendor\nordic\nrf54l_05_10_15.dtsi:293 */
				easydma-maxcnt-bits = < 0x10 >; /* in zephyr\dts\vendor\nordic\nrf54l_05_10_15.dtsi:294 */
				status = "disabled";            /* in zephyr\dts\vendor\nordic\nrf54l_05_10_15.dtsi:295 */
				zephyr,pm-device-runtime-auto;  /* in zephyr\dts\vendor\nordic\nrf54l_05_10_15.dtsi:296 */
			};

			/* node '/soc/peripheral@50000000/spi@c6000' defined in zephyr\dts\vendor\nordic\nrf54l_05_10_15.dtsi:299 */
			spi20: spi@c6000 {
				compatible = "nordic,nrf-spim"; /* in zephyr\dts\vendor\nordic\nrf54l_05_10_15.dtsi:306 */
				#address-cells = < 0x1 >;       /* in zephyr\dts\vendor\nordic\nrf54l_05_10_15.dtsi:307 */
				#size-cells = < 0x0 >;          /* in zephyr\dts\vendor\nordic\nrf54l_05_10_15.dtsi:308 */
				reg = < 0xc6000 0x1000 >;       /* in zephyr\dts\vendor\nordic\nrf54l_05_10_15.dtsi:309 */
				interrupts = < 0xc6 0x1 >;      /* in zephyr\dts\vendor\nordic\nrf54l_05_10_15.dtsi:310 */
				max-frequency = < 0x7a1200 >;   /* in zephyr\dts\vendor\nordic\nrf54l_05_10_15.dtsi:311 */
				easydma-maxcnt-bits = < 0x10 >; /* in zephyr\dts\vendor\nordic\nrf54l_05_10_15.dtsi:312 */
				rx-delay-supported;             /* in zephyr\dts\vendor\nordic\nrf54l_05_10_15.dtsi:313 */
				rx-delay = < 0x1 >;             /* in zephyr\dts\vendor\nordic\nrf54l_05_10_15.dtsi:314 */
				status = "disabled";            /* in zephyr\dts\vendor\nordic\nrf54l_05_10_15.dtsi:315 */
				default-gpio-port = < &gpio1 >; /* in zephyr\dts\vendor\nordic\nrf54l_05_10_15.dtsi:316 */
				cross-domain-pins-supported;    /* in zephyr\dts\vendor\nordic\nrf54l_05_10_15.dtsi:317 */
			};

			/* node '/soc/peripheral@50000000/uart@c6000' defined in zephyr\dts\vendor\nordic\nrf54l_05_10_15.dtsi:320 */
			uart20: uart@c6000 {
				compatible = "nordic,nrf-uarte"; /* in zephyr\dts\vendor\nordic\nrf54l_05_10_15.dtsi:321 */
				reg = < 0xc6000 0x1000 >;        /* in zephyr\dts\vendor\nordic\nrf54l_05_10_15.dtsi:322 */
				interrupts = < 0xc6 0x1 >;       /* in zephyr\dts\vendor\nordic\nrf54l_05_10_15.dtsi:323 */
				status = "okay";                 /* in zephyr\boards\arm\xiao_nrf54l15\xiao_nrf54l15_nrf54l15_cpuapp.dts:75 */
				endtx-stoptx-supported;          /* in zephyr\dts\vendor\nordic\nrf54l_05_10_15.dtsi:325 */
				frame-timeout-supported;         /* in zephyr\dts\vendor\nordic\nrf54l_05_10_15.dtsi:326 */
				default-gpio-port = < &gpio1 >;  /* in zephyr\dts\vendor\nordic\nrf54l_05_10_15.dtsi:327 */
				cross-domain-pins-supported;     /* in zephyr\dts\vendor\nordic\nrf54l_05_10_15.dtsi:328 */
				current-speed = < 0x1c200 >;     /* in zephyr\boards\arm\xiao_nrf54l15\xiao_nrf54l15_common.dtsi:38 */
				pinctrl-0 = < &uart20_default >; /* in zephyr\boards\arm\xiao_nrf54l15\xiao_nrf54l15_common.dtsi:39 */
				pinctrl-1 = < &uart20_sleep >;   /* in zephyr\boards\arm\xiao_nrf54l15\xiao_nrf54l15_common.dtsi:40 */
				pinctrl-names = "default",
				                "sleep";         /* in zephyr\boards\arm\xiao_nrf54l15\xiao_nrf54l15_common.dtsi:41 */
			};

			/* node '/soc/peripheral@50000000/i2c@c7000' defined in zephyr\dts\vendor\nordic\nrf54l_05_10_15.dtsi:331 */
			i2c21: i2c@c7000 {
				compatible = "nordic,nrf-twim"; /* in zephyr\dts\vendor\nordic\nrf54l_05_10_15.dtsi:332 */
				#address-cells = < 0x1 >;       /* in zephyr\dts\vendor\nordic\nrf54l_05_10_15.dtsi:333 */
				#size-cells = < 0x0 >;          /* in zephyr\dts\vendor\nordic\nrf54l_05_10_15.dtsi:334 */
				reg = < 0xc7000 0x1000 >;       /* in zephyr\dts\vendor\nordic\nrf54l_05_10_15.dtsi:335 */
				interrupts = < 0xc7 0x1 >;      /* in zephyr\dts\vendor\nordic\nrf54l_05_10_15.dtsi:336 */
				easydma-maxcnt-bits = < 0x10 >; /* in zephyr\dts\vendor\nordic\nrf54l_05_10_15.dtsi:337 */
				status = "disabled";            /* in zephyr\dts\vendor\nordic\nrf54l_05_10_15.dtsi:338 */
				zephyr,pm-device-runtime-auto;  /* in zephyr\dts\vendor\nordic\nrf54l_05_10_15.dtsi:339 */
			};

			/* node '/soc/peripheral@50000000/spi@c7000' defined in zephyr\dts\vendor\nordic\nrf54l_05_10_15.dtsi:342 */
			spi21: spi@c7000 {
				compatible = "nordic,nrf-spim"; /* in zephyr\dts\vendor\nordic\nrf54l_05_10_15.dtsi:349 */
				#address-cells = < 0x1 >;       /* in zephyr\dts\vendor\nordic\nrf54l_05_10_15.dtsi:350 */
				#size-cells = < 0x0 >;          /* in zephyr\dts\vendor\nordic\nrf54l_05_10_15.dtsi:351 */
				reg = < 0xc7000 0x1000 >;       /* in zephyr\dts\vendor\nordic\nrf54l_05_10_15.dtsi:352 */
				interrupts = < 0xc7 0x1 >;      /* in zephyr\dts\vendor\nordic\nrf54l_05_10_15.dtsi:353 */
				max-frequency = < 0x7a1200 >;   /* in zephyr\dts\vendor\nordic\nrf54l_05_10_15.dtsi:354 */
				easydma-maxcnt-bits = < 0x10 >; /* in zephyr\dts\vendor\nordic\nrf54l_05_10_15.dtsi:355 */
				rx-delay-supported;             /* in zephyr\dts\vendor\nordic\nrf54l_05_10_15.dtsi:356 */
				rx-delay = < 0x1 >;             /* in zephyr\dts\vendor\nordic\nrf54l_05_10_15.dtsi:357 */
				status = "disabled";            /* in zephyr\dts\vendor\nordic\nrf54l_05_10_15.dtsi:358 */
				default-gpio-port = < &gpio1 >; /* in zephyr\dts\vendor\nordic\nrf54l_05_10_15.dtsi:359 */
				cross-domain-pins-supported;    /* in zephyr\dts\vendor\nordic\nrf54l_05_10_15.dtsi:360 */
			};

			/* node '/soc/peripheral@50000000/uart@c7000' defined in zephyr\dts\vendor\nordic\nrf54l_05_10_15.dtsi:363 */
			uart21: xiao_serial: uart@c7000 {
				compatible = "nordic,nrf-uarte"; /* in zephyr\dts\vendor\nordic\nrf54l_05_10_15.dtsi:364 */
				reg = < 0xc7000 0x1000 >;        /* in zephyr\dts\vendor\nordic\nrf54l_05_10_15.dtsi:365 */
				interrupts = < 0xc7 0x1 >;       /* in zephyr\dts\vendor\nordic\nrf54l_05_10_15.dtsi:366 */
				status = "disabled";             /* in zephyr\boards\shields\seeed_xiao_round_display\seeed_xiao_round_display.overlay:62 */
				endtx-stoptx-supported;          /* in zephyr\dts\vendor\nordic\nrf54l_05_10_15.dtsi:368 */
				frame-timeout-supported;         /* in zephyr\dts\vendor\nordic\nrf54l_05_10_15.dtsi:369 */
				default-gpio-port = < &gpio1 >;  /* in zephyr\dts\vendor\nordic\nrf54l_05_10_15.dtsi:370 */
				cross-domain-pins-supported;     /* in zephyr\dts\vendor\nordic\nrf54l_05_10_15.dtsi:371 */
				current-speed = < 0x1c200 >;     /* in zephyr\boards\arm\xiao_nrf54l15\xiao_nrf54l15_common.dtsi:45 */
				pinctrl-0 = < &uart21_default >; /* in zephyr\boards\arm\xiao_nrf54l15\xiao_nrf54l15_common.dtsi:46 */
				pinctrl-1 = < &uart21_sleep >;   /* in zephyr\boards\arm\xiao_nrf54l15\xiao_nrf54l15_common.dtsi:47 */
				pinctrl-names = "default",
				                "sleep";         /* in zephyr\boards\arm\xiao_nrf54l15\xiao_nrf54l15_common.dtsi:48 */
			};

			/* node '/soc/peripheral@50000000/i2c@c8000' defined in zephyr\dts\vendor\nordic\nrf54l_05_10_15.dtsi:374 */
			i2c22: xiao_i2c: i2c@c8000 {
				compatible = "nordic,nrf-twim"; /* in zephyr\dts\vendor\nordic\nrf54l_05_10_15.dtsi:375 */
				#address-cells = < 0x1 >;       /* in zephyr\dts\vendor\nordic\nrf54l_05_10_15.dtsi:376 */
				#size-cells = < 0x0 >;          /* in zephyr\dts\vendor\nordic\nrf54l_05_10_15.dtsi:377 */
				reg = < 0xc8000 0x1000 >;       /* in zephyr\dts\vendor\nordic\nrf54l_05_10_15.dtsi:378 */
				interrupts = < 0xc8 0x1 >;      /* in zephyr\dts\vendor\nordic\nrf54l_05_10_15.dtsi:379 */
				easydma-maxcnt-bits = < 0x10 >; /* in zephyr\dts\vendor\nordic\nrf54l_05_10_15.dtsi:380 */
				status = "okay";                /* in zephyr\boards\arm\xiao_nrf54l15\xiao_nrf54l15_nrf54l15_cpuapp.dts:83 */
				zephyr,pm-device-runtime-auto;  /* in zephyr\dts\vendor\nordic\nrf54l_05_10_15.dtsi:382 */
				pinctrl-0 = < &i2c22_default >; /* in zephyr\boards\arm\xiao_nrf54l15\xiao_nrf54l15_common.dtsi:52 */
				pinctrl-1 = < &i2c22_sleep >;   /* in zephyr\boards\arm\xiao_nrf54l15\xiao_nrf54l15_common.dtsi:53 */
				pinctrl-names = "default",
				                "sleep";        /* in zephyr\boards\arm\xiao_nrf54l15\xiao_nrf54l15_common.dtsi:54 */
				clock-frequency = < 0x61a80 >;  /* in zephyr\boards\shields\seeed_xiao_round_display\seeed_xiao_round_display.overlay:66 */

				/* node '/soc/peripheral@50000000/i2c@c8000/pcf8563@51' defined in zephyr\boards\shields\seeed_xiao_round_display\seeed_xiao_round_display.overlay:68 */
				pcf8563_xiao_round_display: pcf8563@51 {
					status = "okay";            /* in zephyr\boards\shields\seeed_xiao_round_display\seeed_xiao_round_display.overlay:69 */
					compatible = "nxp,pcf8563"; /* in zephyr\boards\shields\seeed_xiao_round_display\seeed_xiao_round_display.overlay:70 */
					reg = < 0x51 >;             /* in zephyr\boards\shields\seeed_xiao_round_display\seeed_xiao_round_display.overlay:71 */
				};

				/* node '/soc/peripheral@50000000/i2c@c8000/chsc6x@2e' defined in zephyr\boards\shields\seeed_xiao_round_display\seeed_xiao_round_display.overlay:74 */
				chsc6x_xiao_round_display: chsc6x@2e {
					status = "okay";                 /* in zephyr\boards\shields\seeed_xiao_round_display\seeed_xiao_round_display.overlay:75 */
					compatible = "chipsemi,chsc6x";  /* in zephyr\boards\shields\seeed_xiao_round_display\seeed_xiao_round_display.overlay:76 */
					reg = < 0x2e >;                  /* in zephyr\boards\shields\seeed_xiao_round_display\seeed_xiao_round_display.overlay:77 */
					irq-gpios = < &xiao_d 0x7 0x1 >; /* in zephyr\boards\shields\seeed_xiao_round_display\seeed_xiao_round_display.overlay:78 */
					phandle = < 0x1a >;              /* in zephyr\boards\shields\seeed_xiao_round_display\seeed_xiao_round_display.overlay:25 */
				};
			};

			/* node '/soc/peripheral@50000000/spi@c8000' defined in zephyr\dts\vendor\nordic\nrf54l_05_10_15.dtsi:385 */
			spi22: spi@c8000 {
				compatible = "nordic,nrf-spim"; /* in zephyr\dts\vendor\nordic\nrf54l_05_10_15.dtsi:392 */
				#address-cells = < 0x1 >;       /* in zephyr\dts\vendor\nordic\nrf54l_05_10_15.dtsi:393 */
				#size-cells = < 0x0 >;          /* in zephyr\dts\vendor\nordic\nrf54l_05_10_15.dtsi:394 */
				reg = < 0xc8000 0x1000 >;       /* in zephyr\dts\vendor\nordic\nrf54l_05_10_15.dtsi:395 */
				interrupts = < 0xc8 0x1 >;      /* in zephyr\dts\vendor\nordic\nrf54l_05_10_15.dtsi:396 */
				max-frequency = < 0x7a1200 >;   /* in zephyr\dts\vendor\nordic\nrf54l_05_10_15.dtsi:397 */
				easydma-maxcnt-bits = < 0x10 >; /* in zephyr\dts\vendor\nordic\nrf54l_05_10_15.dtsi:398 */
				rx-delay-supported;             /* in zephyr\dts\vendor\nordic\nrf54l_05_10_15.dtsi:399 */
				rx-delay = < 0x1 >;             /* in zephyr\dts\vendor\nordic\nrf54l_05_10_15.dtsi:400 */
				status = "disabled";            /* in zephyr\dts\vendor\nordic\nrf54l_05_10_15.dtsi:401 */
				pinctrl-0 = < &spi22_default >; /* in zephyr\boards\arm\xiao_nrf54l15\xiao_nrf54l15_common.dtsi:72 */
				pinctrl-1 = < &spi22_sleep >;   /* in zephyr\boards\arm\xiao_nrf54l15\xiao_nrf54l15_common.dtsi:73 */
				pinctrl-names = "default",
				                "sleep";        /* in zephyr\boards\arm\xiao_nrf54l15\xiao_nrf54l15_common.dtsi:74 */
			};

			/* node '/soc/peripheral@50000000/uart@c8000' defined in zephyr\dts\vendor\nordic\nrf54l_05_10_15.dtsi:404 */
			uart22: uart@c8000 {
				compatible = "nordic,nrf-uarte"; /* in zephyr\dts\vendor\nordic\nrf54l_05_10_15.dtsi:405 */
				reg = < 0xc8000 0x1000 >;        /* in zephyr\dts\vendor\nordic\nrf54l_05_10_15.dtsi:406 */
				interrupts = < 0xc8 0x1 >;       /* in zephyr\dts\vendor\nordic\nrf54l_05_10_15.dtsi:407 */
				status = "disabled";             /* in zephyr\dts\vendor\nordic\nrf54l_05_10_15.dtsi:408 */
				endtx-stoptx-supported;          /* in zephyr\dts\vendor\nordic\nrf54l_05_10_15.dtsi:409 */
				frame-timeout-supported;         /* in zephyr\dts\vendor\nordic\nrf54l_05_10_15.dtsi:410 */
			};

			/* node '/soc/peripheral@50000000/egu@c9000' defined in zephyr\dts\vendor\nordic\nrf54l_05_10_15.dtsi:413 */
			egu20: egu@c9000 {
				compatible = "nordic,nrf-egu"; /* in zephyr\dts\vendor\nordic\nrf54l_05_10_15.dtsi:414 */
				reg = < 0xc9000 0x1000 >;      /* in zephyr\dts\vendor\nordic\nrf54l_05_10_15.dtsi:415 */
				interrupts = < 0xc9 0x1 >;     /* in zephyr\dts\vendor\nordic\nrf54l_05_10_15.dtsi:416 */
				status = "disabled";           /* in zephyr\dts\vendor\nordic\nrf54l_05_10_15.dtsi:417 */
			};

			/* node '/soc/peripheral@50000000/timer@ca000' defined in zephyr\dts\vendor\nordic\nrf54l_05_10_15.dtsi:420 */
			timer20: timer@ca000 {
				compatible = "nordic,nrf-timer"; /* in zephyr\dts\vendor\nordic\nrf54l_05_10_15.dtsi:421 */
				status = "disabled";             /* in zephyr\dts\vendor\nordic\nrf54l_05_10_15.dtsi:422 */
				reg = < 0xca000 0x1000 >;        /* in zephyr\dts\vendor\nordic\nrf54l_05_10_15.dtsi:423 */
				cc-num = < 0x6 >;                /* in zephyr\dts\vendor\nordic\nrf54l_05_10_15.dtsi:424 */
				max-bit-width = < 0x20 >;        /* in zephyr\dts\vendor\nordic\nrf54l_05_10_15.dtsi:425 */
				interrupts = < 0xca 0x1 >;       /* in zephyr\dts\vendor\nordic\nrf54l_05_10_15.dtsi:426 */
				prescaler = < 0x0 >;             /* in zephyr\dts\vendor\nordic\nrf54l_05_10_15.dtsi:427 */
			};

			/* node '/soc/peripheral@50000000/timer@cb000' defined in zephyr\dts\vendor\nordic\nrf54l_05_10_15.dtsi:430 */
			timer21: timer@cb000 {
				compatible = "nordic,nrf-timer"; /* in zephyr\dts\vendor\nordic\nrf54l_05_10_15.dtsi:431 */
				status = "disabled";             /* in zephyr\dts\vendor\nordic\nrf54l_05_10_15.dtsi:432 */
				reg = < 0xcb000 0x1000 >;        /* in zephyr\dts\vendor\nordic\nrf54l_05_10_15.dtsi:433 */
				cc-num = < 0x6 >;                /* in zephyr\dts\vendor\nordic\nrf54l_05_10_15.dtsi:434 */
				max-bit-width = < 0x20 >;        /* in zephyr\dts\vendor\nordic\nrf54l_05_10_15.dtsi:435 */
				interrupts = < 0xcb 0x1 >;       /* in zephyr\dts\vendor\nordic\nrf54l_05_10_15.dtsi:436 */
				prescaler = < 0x0 >;             /* in zephyr\dts\vendor\nordic\nrf54l_05_10_15.dtsi:437 */
			};

			/* node '/soc/peripheral@50000000/timer@cc000' defined in zephyr\dts\vendor\nordic\nrf54l_05_10_15.dtsi:440 */
			timer22: timer@cc000 {
				compatible = "nordic,nrf-timer"; /* in zephyr\dts\vendor\nordic\nrf54l_05_10_15.dtsi:441 */
				status = "disabled";             /* in zephyr\dts\vendor\nordic\nrf54l_05_10_15.dtsi:442 */
				reg = < 0xcc000 0x1000 >;        /* in zephyr\dts\vendor\nordic\nrf54l_05_10_15.dtsi:443 */
				cc-num = < 0x6 >;                /* in zephyr\dts\vendor\nordic\nrf54l_05_10_15.dtsi:444 */
				max-bit-width = < 0x20 >;        /* in zephyr\dts\vendor\nordic\nrf54l_05_10_15.dtsi:445 */
				interrupts = < 0xcc 0x1 >;       /* in zephyr\dts\vendor\nordic\nrf54l_05_10_15.dtsi:446 */
				prescaler = < 0x0 >;             /* in zephyr\dts\vendor\nordic\nrf54l_05_10_15.dtsi:447 */
			};

			/* node '/soc/peripheral@50000000/timer@cd000' defined in zephyr\dts\vendor\nordic\nrf54l_05_10_15.dtsi:450 */
			timer23: timer@cd000 {
				compatible = "nordic,nrf-timer"; /* in zephyr\dts\vendor\nordic\nrf54l_05_10_15.dtsi:451 */
				status = "disabled";             /* in zephyr\dts\vendor\nordic\nrf54l_05_10_15.dtsi:452 */
				reg = < 0xcd000 0x1000 >;        /* in zephyr\dts\vendor\nordic\nrf54l_05_10_15.dtsi:453 */
				cc-num = < 0x6 >;                /* in zephyr\dts\vendor\nordic\nrf54l_05_10_15.dtsi:454 */
				max-bit-width = < 0x20 >;        /* in zephyr\dts\vendor\nordic\nrf54l_05_10_15.dtsi:455 */
				interrupts = < 0xcd 0x1 >;       /* in zephyr\dts\vendor\nordic\nrf54l_05_10_15.dtsi:456 */
				prescaler = < 0x0 >;             /* in zephyr\dts\vendor\nordic\nrf54l_05_10_15.dtsi:457 */
			};

			/* node '/soc/peripheral@50000000/timer@ce000' defined in zephyr\dts\vendor\nordic\nrf54l_05_10_15.dtsi:460 */
			timer24: timer@ce000 {
				compatible = "nordic,nrf-timer"; /* in zephyr\dts\vendor\nordic\nrf54l_05_10_15.dtsi:461 */
				status = "disabled";             /* in zephyr\dts\vendor\nordic\nrf54l_05_10_15.dtsi:462 */
				reg = < 0xce000 0x1000 >;        /* in zephyr\dts\vendor\nordic\nrf54l_05_10_15.dtsi:463 */
				cc-num = < 0x6 >;                /* in zephyr\dts\vendor\nordic\nrf54l_05_10_15.dtsi:464 */
				max-bit-width = < 0x20 >;        /* in zephyr\dts\vendor\nordic\nrf54l_05_10_15.dtsi:465 */
				interrupts = < 0xce 0x1 >;       /* in zephyr\dts\vendor\nordic\nrf54l_05_10_15.dtsi:466 */
				prescaler = < 0x0 >;             /* in zephyr\dts\vendor\nordic\nrf54l_05_10_15.dtsi:467 */
			};

			/* node '/soc/peripheral@50000000/pdm@d0000' defined in zephyr\dts\vendor\nordic\nrf54l_05_10_15.dtsi:470 */
			pdm20: pdm@d0000 {
				compatible = "nordic,nrf-pdm";  /* in zephyr\dts\vendor\nordic\nrf54l_05_10_15.dtsi:471 */
				status = "okay";                /* in zephyr\boards\arm\xiao_nrf54l15\xiao_nrf54l15_nrf54l15_cpuapp.dts:104 */
				reg = < 0xd0000 0x1000 >;       /* in zephyr\dts\vendor\nordic\nrf54l_05_10_15.dtsi:473 */
				interrupts = < 0xd0 0x1 >;      /* in zephyr\dts\vendor\nordic\nrf54l_05_10_15.dtsi:474 */
				pinctrl-0 = < &pdm20_default >; /* in zephyr\boards\arm\xiao_nrf54l15\xiao_nrf54l15_common.dtsi:78 */
				pinctrl-names = "default";      /* in zephyr\boards\arm\xiao_nrf54l15\xiao_nrf54l15_common.dtsi:79 */
				clock-source = "PCLK32M";       /* in zephyr\boards\arm\xiao_nrf54l15\xiao_nrf54l15_common.dtsi:80 */
			};

			/* node '/soc/peripheral@50000000/pdm@d1000' defined in zephyr\dts\vendor\nordic\nrf54l_05_10_15.dtsi:477 */
			pdm21: pdm@d1000 {
				compatible = "nordic,nrf-pdm"; /* in zephyr\dts\vendor\nordic\nrf54l_05_10_15.dtsi:478 */
				status = "disabled";           /* in zephyr\dts\vendor\nordic\nrf54l_05_10_15.dtsi:479 */
				reg = < 0xd1000 0x1000 >;      /* in zephyr\dts\vendor\nordic\nrf54l_05_10_15.dtsi:480 */
				interrupts = < 0xd1 0x1 >;     /* in zephyr\dts\vendor\nordic\nrf54l_05_10_15.dtsi:481 */
			};

			/* node '/soc/peripheral@50000000/pwm@d2000' defined in zephyr\dts\vendor\nordic\nrf54l_05_10_15.dtsi:484 */
			pwm20: pwm@d2000 {
				compatible = "nordic,nrf-pwm"; /* in zephyr\dts\vendor\nordic\nrf54l_05_10_15.dtsi:485 */
				status = "disabled";           /* in zephyr\dts\vendor\nordic\nrf54l_05_10_15.dtsi:486 */
				reg = < 0xd2000 0x1000 >;      /* in zephyr\dts\vendor\nordic\nrf54l_05_10_15.dtsi:487 */
				interrupts = < 0xd2 0x1 >;     /* in zephyr\dts\vendor\nordic\nrf54l_05_10_15.dtsi:488 */
				#pwm-cells = < 0x3 >;          /* in zephyr\dts\vendor\nordic\nrf54l_05_10_15.dtsi:489 */
				idleout-supported;             /* in zephyr\dts\vendor\nordic\nrf54l_05_10_15.dtsi:490 */
			};

			/* node '/soc/peripheral@50000000/pwm@d3000' defined in zephyr\dts\vendor\nordic\nrf54l_05_10_15.dtsi:493 */
			pwm21: pwm@d3000 {
				compatible = "nordic,nrf-pwm"; /* in zephyr\dts\vendor\nordic\nrf54l_05_10_15.dtsi:494 */
				status = "disabled";           /* in zephyr\dts\vendor\nordic\nrf54l_05_10_15.dtsi:495 */
				reg = < 0xd3000 0x1000 >;      /* in zephyr\dts\vendor\nordic\nrf54l_05_10_15.dtsi:496 */
				interrupts = < 0xd3 0x1 >;     /* in zephyr\dts\vendor\nordic\nrf54l_05_10_15.dtsi:497 */
				#pwm-cells = < 0x3 >;          /* in zephyr\dts\vendor\nordic\nrf54l_05_10_15.dtsi:498 */
				idleout-supported;             /* in zephyr\dts\vendor\nordic\nrf54l_05_10_15.dtsi:499 */
			};

			/* node '/soc/peripheral@50000000/pwm@d4000' defined in zephyr\dts\vendor\nordic\nrf54l_05_10_15.dtsi:502 */
			pwm22: pwm@d4000 {
				compatible = "nordic,nrf-pwm"; /* in zephyr\dts\vendor\nordic\nrf54l_05_10_15.dtsi:503 */
				status = "disabled";           /* in zephyr\dts\vendor\nordic\nrf54l_05_10_15.dtsi:504 */
				reg = < 0xd4000 0x1000 >;      /* in zephyr\dts\vendor\nordic\nrf54l_05_10_15.dtsi:505 */
				interrupts = < 0xd4 0x1 >;     /* in zephyr\dts\vendor\nordic\nrf54l_05_10_15.dtsi:506 */
				#pwm-cells = < 0x3 >;          /* in zephyr\dts\vendor\nordic\nrf54l_05_10_15.dtsi:507 */
				idleout-supported;             /* in zephyr\dts\vendor\nordic\nrf54l_05_10_15.dtsi:508 */
			};

			/* node '/soc/peripheral@50000000/adc@d5000' defined in zephyr\dts\vendor\nordic\nrf54l_05_10_15.dtsi:511 */
			adc: xiao_adc: adc@d5000 {
				compatible = "nordic,nrf-saadc"; /* in zephyr\dts\vendor\nordic\nrf54l_05_10_15.dtsi:512 */
				reg = < 0xd5000 0x1000 >;        /* in zephyr\dts\vendor\nordic\nrf54l_05_10_15.dtsi:513 */
				interrupts = < 0xd5 0x1 >;       /* in zephyr\dts\vendor\nordic\nrf54l_05_10_15.dtsi:514 */
				status = "okay";                 /* in zephyr\boards\shields\seeed_xiao_round_display\seeed_xiao_round_display.overlay:54 */
				#io-channel-cells = < 0x1 >;     /* in zephyr\dts\vendor\nordic\nrf54l_05_10_15.dtsi:516 */
				zephyr,pm-device-runtime-auto;   /* in zephyr\dts\vendor\nordic\nrf54l_05_10_15.dtsi:517 */
				#address-cells = < 0x1 >;        /* in zephyr\boards\arm\xiao_nrf54l15\xiao_nrf54l15_common.dtsi:85 */
				#size-cells = < 0x0 >;           /* in zephyr\boards\arm\xiao_nrf54l15\xiao_nrf54l15_common.dtsi:86 */
				phandle = < 0x19 >;              /* in zephyr\boards\shields\seeed_xiao_round_display\seeed_xiao_round_display.overlay:18 */

				/* node '/soc/peripheral@50000000/adc@d5000/channel@0' defined in zephyr\boards\arm\xiao_nrf54l15\xiao_nrf54l15_common.dtsi:88 */
				channel@0 {
					reg = < 0x0 >;                         /* in zephyr\boards\arm\xiao_nrf54l15\xiao_nrf54l15_common.dtsi:89 */
					zephyr,gain = "ADC_GAIN_1_4";          /* in zephyr\boards\arm\xiao_nrf54l15\xiao_nrf54l15_common.dtsi:90 */
					zephyr,reference = "ADC_REF_INTERNAL"; /* in zephyr\boards\arm\xiao_nrf54l15\xiao_nrf54l15_common.dtsi:91 */
					zephyr,acquisition-time = < 0x0 >;     /* in zephyr\boards\arm\xiao_nrf54l15\xiao_nrf54l15_common.dtsi:92 */
					zephyr,input-positive = < 0x1 >;       /* in zephyr\boards\arm\xiao_nrf54l15\xiao_nrf54l15_common.dtsi:93 */
					zephyr,resolution = < 0xc >;           /* in zephyr\boards\arm\xiao_nrf54l15\xiao_nrf54l15_common.dtsi:94 */
					zephyr,oversampling = < 0x8 >;         /* in zephyr\boards\arm\xiao_nrf54l15\xiao_nrf54l15_common.dtsi:95 */
				};

				/* node '/soc/peripheral@50000000/adc@d5000/channel@1' defined in zephyr\boards\arm\xiao_nrf54l15\xiao_nrf54l15_common.dtsi:98 */
				channel@1 {
					reg = < 0x1 >;                         /* in zephyr\boards\arm\xiao_nrf54l15\xiao_nrf54l15_common.dtsi:99 */
					zephyr,gain = "ADC_GAIN_1_4";          /* in zephyr\boards\arm\xiao_nrf54l15\xiao_nrf54l15_common.dtsi:100 */
					zephyr,reference = "ADC_REF_INTERNAL"; /* in zephyr\boards\arm\xiao_nrf54l15\xiao_nrf54l15_common.dtsi:101 */
					zephyr,acquisition-time = < 0x0 >;     /* in zephyr\boards\arm\xiao_nrf54l15\xiao_nrf54l15_common.dtsi:102 */
					zephyr,input-positive = < 0x2 >;       /* in zephyr\boards\arm\xiao_nrf54l15\xiao_nrf54l15_common.dtsi:103 */
					zephyr,resolution = < 0xc >;           /* in zephyr\boards\arm\xiao_nrf54l15\xiao_nrf54l15_common.dtsi:104 */
					zephyr,oversampling = < 0x8 >;         /* in zephyr\boards\arm\xiao_nrf54l15\xiao_nrf54l15_common.dtsi:105 */
				};

				/* node '/soc/peripheral@50000000/adc@d5000/channel@2' defined in zephyr\boards\arm\xiao_nrf54l15\xiao_nrf54l15_common.dtsi:108 */
				channel@2 {
					reg = < 0x2 >;                         /* in zephyr\boards\arm\xiao_nrf54l15\xiao_nrf54l15_common.dtsi:109 */
					zephyr,gain = "ADC_GAIN_1_4";          /* in zephyr\boards\arm\xiao_nrf54l15\xiao_nrf54l15_common.dtsi:110 */
					zephyr,reference = "ADC_REF_INTERNAL"; /* in zephyr\boards\arm\xiao_nrf54l15\xiao_nrf54l15_common.dtsi:111 */
					zephyr,acquisition-time = < 0x0 >;     /* in zephyr\boards\arm\xiao_nrf54l15\xiao_nrf54l15_common.dtsi:112 */
					zephyr,input-positive = < 0x3 >;       /* in zephyr\boards\arm\xiao_nrf54l15\xiao_nrf54l15_common.dtsi:113 */
					zephyr,resolution = < 0xc >;           /* in zephyr\boards\arm\xiao_nrf54l15\xiao_nrf54l15_common.dtsi:114 */
					zephyr,oversampling = < 0x8 >;         /* in zephyr\boards\arm\xiao_nrf54l15\xiao_nrf54l15_common.dtsi:115 */
				};

				/* node '/soc/peripheral@50000000/adc@d5000/channel@3' defined in zephyr\boards\arm\xiao_nrf54l15\xiao_nrf54l15_common.dtsi:118 */
				channel@3 {
					reg = < 0x3 >;                         /* in zephyr\boards\arm\xiao_nrf54l15\xiao_nrf54l15_common.dtsi:119 */
					zephyr,gain = "ADC_GAIN_1_4";          /* in zephyr\boards\arm\xiao_nrf54l15\xiao_nrf54l15_common.dtsi:120 */
					zephyr,reference = "ADC_REF_INTERNAL"; /* in zephyr\boards\arm\xiao_nrf54l15\xiao_nrf54l15_common.dtsi:121 */
					zephyr,acquisition-time = < 0x0 >;     /* in zephyr\boards\arm\xiao_nrf54l15\xiao_nrf54l15_common.dtsi:122 */
					zephyr,input-positive = < 0x4 >;       /* in zephyr\boards\arm\xiao_nrf54l15\xiao_nrf54l15_common.dtsi:123 */
					zephyr,resolution = < 0xc >;           /* in zephyr\boards\arm\xiao_nrf54l15\xiao_nrf54l15_common.dtsi:124 */
					zephyr,oversampling = < 0x8 >;         /* in zephyr\boards\arm\xiao_nrf54l15\xiao_nrf54l15_common.dtsi:125 */
				};

				/* node '/soc/peripheral@50000000/adc@d5000/channel@4' defined in zephyr\boards\arm\xiao_nrf54l15\xiao_nrf54l15_common.dtsi:128 */
				channel@4 {
					reg = < 0x4 >;                         /* in zephyr\boards\arm\xiao_nrf54l15\xiao_nrf54l15_common.dtsi:129 */
					zephyr,gain = "ADC_GAIN_1_4";          /* in zephyr\boards\arm\xiao_nrf54l15\xiao_nrf54l15_common.dtsi:130 */
					zephyr,reference = "ADC_REF_INTERNAL"; /* in zephyr\boards\arm\xiao_nrf54l15\xiao_nrf54l15_common.dtsi:131 */
					zephyr,acquisition-time = < 0x0 >;     /* in zephyr\boards\arm\xiao_nrf54l15\xiao_nrf54l15_common.dtsi:132 */
					zephyr,input-positive = < 0x5 >;       /* in zephyr\boards\arm\xiao_nrf54l15\xiao_nrf54l15_common.dtsi:133 */
					zephyr,resolution = < 0xc >;           /* in zephyr\boards\arm\xiao_nrf54l15\xiao_nrf54l15_common.dtsi:134 */
					zephyr,oversampling = < 0x8 >;         /* in zephyr\boards\arm\xiao_nrf54l15\xiao_nrf54l15_common.dtsi:135 */
				};

				/* node '/soc/peripheral@50000000/adc@d5000/channel@5' defined in zephyr\boards\arm\xiao_nrf54l15\xiao_nrf54l15_common.dtsi:138 */
				channel@5 {
					reg = < 0x5 >;                         /* in zephyr\boards\arm\xiao_nrf54l15\xiao_nrf54l15_common.dtsi:139 */
					zephyr,gain = "ADC_GAIN_1_4";          /* in zephyr\boards\arm\xiao_nrf54l15\xiao_nrf54l15_common.dtsi:140 */
					zephyr,reference = "ADC_REF_INTERNAL"; /* in zephyr\boards\arm\xiao_nrf54l15\xiao_nrf54l15_common.dtsi:141 */
					zephyr,acquisition-time = < 0x0 >;     /* in zephyr\boards\arm\xiao_nrf54l15\xiao_nrf54l15_common.dtsi:142 */
					zephyr,input-positive = < 0x6 >;       /* in zephyr\boards\arm\xiao_nrf54l15\xiao_nrf54l15_common.dtsi:143 */
					zephyr,resolution = < 0xc >;           /* in zephyr\boards\arm\xiao_nrf54l15\xiao_nrf54l15_common.dtsi:144 */
					zephyr,oversampling = < 0x8 >;         /* in zephyr\boards\arm\xiao_nrf54l15\xiao_nrf54l15_common.dtsi:145 */
				};

				/* node '/soc/peripheral@50000000/adc@d5000/channel@6' defined in zephyr\boards\arm\xiao_nrf54l15\xiao_nrf54l15_common.dtsi:148 */
				channel@6 {
					reg = < 0x6 >;                         /* in zephyr\boards\arm\xiao_nrf54l15\xiao_nrf54l15_common.dtsi:149 */
					zephyr,gain = "ADC_GAIN_1_4";          /* in zephyr\boards\arm\xiao_nrf54l15\xiao_nrf54l15_common.dtsi:150 */
					zephyr,reference = "ADC_REF_INTERNAL"; /* in zephyr\boards\arm\xiao_nrf54l15\xiao_nrf54l15_common.dtsi:151 */
					zephyr,acquisition-time = < 0x0 >;     /* in zephyr\boards\arm\xiao_nrf54l15\xiao_nrf54l15_common.dtsi:152 */
					zephyr,input-positive = < 0x7 >;       /* in zephyr\boards\arm\xiao_nrf54l15\xiao_nrf54l15_common.dtsi:153 */
					zephyr,resolution = < 0xc >;           /* in zephyr\boards\arm\xiao_nrf54l15\xiao_nrf54l15_common.dtsi:154 */
					zephyr,oversampling = < 0x8 >;         /* in zephyr\boards\arm\xiao_nrf54l15\xiao_nrf54l15_common.dtsi:155 */
				};

				/* node '/soc/peripheral@50000000/adc@d5000/channel@7' defined in zephyr\boards\arm\xiao_nrf54l15\xiao_nrf54l15_common.dtsi:158 */
				channel@7 {
					reg = < 0x7 >;                         /* in zephyr\boards\arm\xiao_nrf54l15\xiao_nrf54l15_common.dtsi:159 */
					zephyr,gain = "ADC_GAIN_1_4";          /* in zephyr\boards\arm\xiao_nrf54l15\xiao_nrf54l15_common.dtsi:160 */
					zephyr,reference = "ADC_REF_INTERNAL"; /* in zephyr\boards\arm\xiao_nrf54l15\xiao_nrf54l15_common.dtsi:161 */
					zephyr,acquisition-time = < 0x0 >;     /* in zephyr\boards\arm\xiao_nrf54l15\xiao_nrf54l15_common.dtsi:162 */
					zephyr,input-positive = < 0x8 >;       /* in zephyr\boards\arm\xiao_nrf54l15\xiao_nrf54l15_common.dtsi:163 */
					zephyr,resolution = < 0xc >;           /* in zephyr\boards\arm\xiao_nrf54l15\xiao_nrf54l15_common.dtsi:164 */
					zephyr,oversampling = < 0x8 >;         /* in zephyr\boards\arm\xiao_nrf54l15\xiao_nrf54l15_common.dtsi:165 */
				};
			};

			/* node '/soc/peripheral@50000000/nfct@d6000' defined in zephyr\dts\vendor\nordic\nrf54l_05_10_15.dtsi:520 */
			nfct: nfct@d6000 {
				compatible = "nordic,nrf-nfct"; /* in zephyr\dts\vendor\nordic\nrf54l_05_10_15.dtsi:521 */
				reg = < 0xd6000 0x1000 >;       /* in zephyr\dts\vendor\nordic\nrf54l_05_10_15.dtsi:522 */
				interrupts = < 0xd6 0x1 >;      /* in zephyr\dts\vendor\nordic\nrf54l_05_10_15.dtsi:523 */
				status = "okay";                /* in zephyr\boards\arm\xiao_nrf54l15\xiao_nrf54l15_nrf54l15_cpuapp.dts:172 */
			};

			/* node '/soc/peripheral@50000000/temp@d7000' defined in zephyr\dts\vendor\nordic\nrf54l_05_10_15.dtsi:527 */
			temp: temp@d7000 {
				compatible = "nordic,nrf-temp"; /* in zephyr\dts\vendor\nordic\nrf54l_05_10_15.dtsi:528 */
				reg = < 0xd7000 0x1000 >;       /* in zephyr\dts\vendor\nordic\nrf54l_05_10_15.dtsi:529 */
				interrupts = < 0xd7 0x1 >;      /* in zephyr\dts\vendor\nordic\nrf54l_05_10_15.dtsi:530 */
				status = "okay";                /* in zephyr\boards\arm\xiao_nrf54l15\xiao_nrf54l15_nrf54l15_cpuapp.dts:164 */
			};

			/* node '/soc/peripheral@50000000/gpio@d8200' defined in zephyr\dts\vendor\nordic\nrf54l_05_10_15.dtsi:534 */
			gpio1: gpio@d8200 {
				compatible = "nordic,nrf-gpio";  /* in zephyr\dts\vendor\nordic\nrf54l_05_10_15.dtsi:535 */
				gpio-controller;                 /* in zephyr\dts\vendor\nordic\nrf54l_05_10_15.dtsi:536 */
				reg = < 0xd8200 0x300 >;         /* in zephyr\dts\vendor\nordic\nrf54l_05_10_15.dtsi:537 */
				#gpio-cells = < 0x2 >;           /* in zephyr\dts\vendor\nordic\nrf54l_05_10_15.dtsi:538 */
				ngpios = < 0x10 >;               /* in zephyr\dts\vendor\nordic\nrf54l_05_10_15.dtsi:539 */
				status = "okay";                 /* in zephyr\boards\arm\xiao_nrf54l15\xiao_nrf54l15_nrf54l15_cpuapp.dts:122 */
				port = < 0x1 >;                  /* in zephyr\dts\vendor\nordic\nrf54l_05_10_15.dtsi:541 */
				gpiote-instance = < &gpiote20 >; /* in zephyr\dts\vendor\nordic\nrf54l_05_10_15.dtsi:542 */
				phandle = < 0x7 >;               /* in zephyr\dts\vendor\nordic\nrf54l_05_10_15.dtsi:316 */
			};

			/* node '/soc/peripheral@50000000/gpiote@da000' defined in zephyr\dts\vendor\nordic\nrf54l_05_10_15.dtsi:545 */
			gpiote20: gpiote@da000 {
				compatible = "nordic,nrf-gpiote"; /* in zephyr\dts\vendor\nordic\nrf54l_05_10_15.dtsi:546 */
				reg = < 0xda000 0x1000 >;         /* in zephyr\dts\vendor\nordic\nrf54l_05_10_15.dtsi:547 */
				status = "okay";                  /* in zephyr\boards\arm\xiao_nrf54l15\xiao_nrf54l15_nrf54l15_cpuapp.dts:130 */
				instance = < 0x14 >;              /* in zephyr\dts\vendor\nordic\nrf54l_05_10_15.dtsi:549 */
				interrupts = < 0xdb 0x1 >;        /* in zephyr\dts\arm\nordic\nrf54l_05_10_15_cpuapp.dtsi:83 */
				phandle = < 0x11 >;               /* in zephyr\dts\vendor\nordic\nrf54l_05_10_15.dtsi:542 */
			};

			/* node '/soc/peripheral@50000000/i2s@dd000' defined in zephyr\dts\vendor\nordic\nrf54l_05_10_15.dtsi:552 */
			i2s20: i2s@dd000 {
				compatible = "nordic,nrf-i2s"; /* in zephyr\dts\vendor\nordic\nrf54l_05_10_15.dtsi:553 */
				#address-cells = < 0x1 >;      /* in zephyr\dts\vendor\nordic\nrf54l_05_10_15.dtsi:554 */
				#size-cells = < 0x0 >;         /* in zephyr\dts\vendor\nordic\nrf54l_05_10_15.dtsi:555 */
				reg = < 0xdd000 0x1000 >;      /* in zephyr\dts\vendor\nordic\nrf54l_05_10_15.dtsi:556 */
				interrupts = < 0xdd 0x1 >;     /* in zephyr\dts\vendor\nordic\nrf54l_05_10_15.dtsi:557 */
				status = "disabled";           /* in zephyr\dts\vendor\nordic\nrf54l_05_10_15.dtsi:558 */
			};

			/* node '/soc/peripheral@50000000/qdec@e0000' defined in zephyr\dts\vendor\nordic\nrf54l_05_10_15.dtsi:561 */
			qdec20: qdec@e0000 {
				compatible = "nordic,nrf-qdec"; /* in zephyr\dts\vendor\nordic\nrf54l_05_10_15.dtsi:562 */
				reg = < 0xe0000 0x1000 >;       /* in zephyr\dts\vendor\nordic\nrf54l_05_10_15.dtsi:563 */
				interrupts = < 0xe0 0x1 >;      /* in zephyr\dts\vendor\nordic\nrf54l_05_10_15.dtsi:564 */
				status = "disabled";            /* in zephyr\dts\vendor\nordic\nrf54l_05_10_15.dtsi:565 */
			};

			/* node '/soc/peripheral@50000000/qdec@e1000' defined in zephyr\dts\vendor\nordic\nrf54l_05_10_15.dtsi:568 */
			qdec21: qdec@e1000 {
				compatible = "nordic,nrf-qdec"; /* in zephyr\dts\vendor\nordic\nrf54l_05_10_15.dtsi:569 */
				reg = < 0xe1000 0x1000 >;       /* in zephyr\dts\vendor\nordic\nrf54l_05_10_15.dtsi:570 */
				interrupts = < 0xe1 0x1 >;      /* in zephyr\dts\vendor\nordic\nrf54l_05_10_15.dtsi:571 */
				status = "disabled";            /* in zephyr\dts\vendor\nordic\nrf54l_05_10_15.dtsi:572 */
			};

			/* node '/soc/peripheral@50000000/grtc@e2000' defined in zephyr\dts\vendor\nordic\nrf54l_05_10_15.dtsi:575 */
			grtc: grtc@e2000 {
				compatible = "nordic,nrf-grtc";                                       /* in zephyr\dts\vendor\nordic\nrf54l_05_10_15.dtsi:576 */
				reg = < 0xe2000 0x1000 >;                                             /* in zephyr\dts\vendor\nordic\nrf54l_05_10_15.dtsi:577 */
				cc-num = < 0xc >;                                                     /* in zephyr\dts\vendor\nordic\nrf54l_05_10_15.dtsi:578 */
				clocks = < &lfxo >,
				         < &pclk >;                                                   /* in zephyr\dts\vendor\nordic\nrf54l_05_10_15.dtsi:579 */
				clock-names = "lfclock",
				              "hfclock";                                              /* in zephyr\dts\vendor\nordic\nrf54l_05_10_15.dtsi:580 */
				status = "okay";                                                      /* in zephyr\boards\arm\xiao_nrf54l15\xiao_nrf54l15_nrf54l15_cpuapp.dts:67 */
				interrupts = < 0xe4 0x1 >,
				             < 0xe5 0x1 >;                                            /* in zephyr\dts\arm\nordic\nrf54l_05_10_15_cpuapp.dtsi:74 */
				owned-channels = < 0x0 0x1 0x2 0x3 0x4 0x5 0x6 0x7 0x8 0x9 0xa 0xb >; /* in zephyr\boards\arm\xiao_nrf54l15\xiao_nrf54l15_nrf54l15_cpuapp.dts:64 */
				child-owned-channels = < 0x3 0x4 0x7 0x8 0x9 0xa 0xb >;               /* in zephyr\boards\arm\xiao_nrf54l15\xiao_nrf54l15_nrf54l15_cpuapp.dts:66 */
			};

			/* node '/soc/peripheral@50000000/dppic@102000' defined in zephyr\dts\vendor\nordic\nrf54l_05_10_15.dtsi:584 */
			dppic30: dppic@102000 {
				compatible = "nordic,nrf-dppic"; /* in zephyr\dts\vendor\nordic\nrf54l_05_10_15.dtsi:585 */
				reg = < 0x102000 0x808 >;        /* in zephyr\dts\vendor\nordic\nrf54l_05_10_15.dtsi:586 */
				status = "okay";                 /* in zephyr\dts\arm\nordic\nrf54l_05_10_15_cpuapp.dtsi:108 */
			};

			/* node '/soc/peripheral@50000000/ppib@103000' defined in zephyr\dts\vendor\nordic\nrf54l_05_10_15.dtsi:590 */
			ppib30: ppib@103000 {
				compatible = "nordic,nrf-ppib"; /* in zephyr\dts\vendor\nordic\nrf54l_05_10_15.dtsi:591 */
				reg = < 0x103000 0x1000 >;      /* in zephyr\dts\vendor\nordic\nrf54l_05_10_15.dtsi:592 */
				status = "okay";                /* in zephyr\dts\arm\nordic\nrf54l_05_10_15_cpuapp.dtsi:140 */
			};

			/* node '/soc/peripheral@50000000/i2c@104000' defined in zephyr\dts\vendor\nordic\nrf54l_05_10_15.dtsi:596 */
			i2c30: i2c@104000 {
				compatible = "nordic,nrf-twim"; /* in zephyr\dts\vendor\nordic\nrf54l_05_10_15.dtsi:597 */
				#address-cells = < 0x1 >;       /* in zephyr\dts\vendor\nordic\nrf54l_05_10_15.dtsi:598 */
				#size-cells = < 0x0 >;          /* in zephyr\dts\vendor\nordic\nrf54l_05_10_15.dtsi:599 */
				reg = < 0x104000 0x1000 >;      /* in zephyr\dts\vendor\nordic\nrf54l_05_10_15.dtsi:600 */
				interrupts = < 0x104 0x1 >;     /* in zephyr\dts\vendor\nordic\nrf54l_05_10_15.dtsi:601 */
				easydma-maxcnt-bits = < 0x10 >; /* in zephyr\dts\vendor\nordic\nrf54l_05_10_15.dtsi:602 */
				status = "okay";                /* in zephyr\boards\arm\xiao_nrf54l15\xiao_nrf54l15_nrf54l15_cpuapp.dts:87 */
				zephyr,pm-device-runtime-auto;  /* in zephyr\dts\vendor\nordic\nrf54l_05_10_15.dtsi:604 */
				pinctrl-0 = < &i2c30_default >; /* in zephyr\boards\arm\xiao_nrf54l15\xiao_nrf54l15_common.dtsi:59 */
				pinctrl-1 = < &i2c30_sleep >;   /* in zephyr\boards\arm\xiao_nrf54l15\xiao_nrf54l15_common.dtsi:60 */
				pinctrl-names = "default",
				                "sleep";        /* in zephyr\boards\arm\xiao_nrf54l15\xiao_nrf54l15_common.dtsi:61 */
				clock-frequency = < 0x61a80 >;  /* in zephyr\boards\arm\xiao_nrf54l15\xiao_nrf54l15_common.dtsi:62 */

				/* node '/soc/peripheral@50000000/i2c@104000/lsm6dso@6a' defined in zephyr\boards\arm\xiao_nrf54l15\xiao_nrf54l15_nrf54l15_cpuapp.dts:89 */
				lsm6dso: lsm6dso@6a {
					compatible = "st,lsm6dso";      /* in zephyr\boards\arm\xiao_nrf54l15\xiao_nrf54l15_nrf54l15_cpuapp.dts:90 */
					reg = < 0x6a >;                 /* in zephyr\boards\arm\xiao_nrf54l15\xiao_nrf54l15_nrf54l15_cpuapp.dts:91 */
					irq-gpios = < &gpio0 0x2 0x0 >; /* in zephyr\boards\arm\xiao_nrf54l15\xiao_nrf54l15_nrf54l15_cpuapp.dts:92 */
					accel-pm = < 0x2 >;             /* in zephyr\boards\arm\xiao_nrf54l15\xiao_nrf54l15_nrf54l15_cpuapp.dts:93 */
					gyro-pm = < 0x1 >;              /* in zephyr\boards\arm\xiao_nrf54l15\xiao_nrf54l15_nrf54l15_cpuapp.dts:94 */
					status = "okay";                /* in zephyr\boards\arm\xiao_nrf54l15\xiao_nrf54l15_nrf54l15_cpuapp.dts:95 */
				};
			};

			/* node '/soc/peripheral@50000000/spi@104000' defined in zephyr\dts\vendor\nordic\nrf54l_05_10_15.dtsi:607 */
			spi30: spi@104000 {
				compatible = "nordic,nrf-spim"; /* in zephyr\dts\vendor\nordic\nrf54l_05_10_15.dtsi:614 */
				#address-cells = < 0x1 >;       /* in zephyr\dts\vendor\nordic\nrf54l_05_10_15.dtsi:615 */
				#size-cells = < 0x0 >;          /* in zephyr\dts\vendor\nordic\nrf54l_05_10_15.dtsi:616 */
				reg = < 0x104000 0x1000 >;      /* in zephyr\dts\vendor\nordic\nrf54l_05_10_15.dtsi:617 */
				interrupts = < 0x104 0x1 >;     /* in zephyr\dts\vendor\nordic\nrf54l_05_10_15.dtsi:618 */
				max-frequency = < 0x7a1200 >;   /* in zephyr\dts\vendor\nordic\nrf54l_05_10_15.dtsi:619 */
				easydma-maxcnt-bits = < 0x10 >; /* in zephyr\dts\vendor\nordic\nrf54l_05_10_15.dtsi:620 */
				rx-delay-supported;             /* in zephyr\dts\vendor\nordic\nrf54l_05_10_15.dtsi:621 */
				rx-delay = < 0x1 >;             /* in zephyr\dts\vendor\nordic\nrf54l_05_10_15.dtsi:622 */
				status = "disabled";            /* in zephyr\dts\vendor\nordic\nrf54l_05_10_15.dtsi:623 */
			};

			/* node '/soc/peripheral@50000000/uart@104000' defined in zephyr\dts\vendor\nordic\nrf54l_05_10_15.dtsi:626 */
			uart30: uart@104000 {
				compatible = "nordic,nrf-uarte"; /* in zephyr\dts\vendor\nordic\nrf54l_05_10_15.dtsi:627 */
				reg = < 0x104000 0x1000 >;       /* in zephyr\dts\vendor\nordic\nrf54l_05_10_15.dtsi:628 */
				interrupts = < 0x104 0x1 >;      /* in zephyr\dts\vendor\nordic\nrf54l_05_10_15.dtsi:629 */
				status = "disabled";             /* in zephyr\dts\vendor\nordic\nrf54l_05_10_15.dtsi:630 */
				endtx-stoptx-supported;          /* in zephyr\dts\vendor\nordic\nrf54l_05_10_15.dtsi:631 */
				frame-timeout-supported;         /* in zephyr\dts\vendor\nordic\nrf54l_05_10_15.dtsi:632 */
			};

			/* node '/soc/peripheral@50000000/clock@10e000' defined in zephyr\dts\vendor\nordic\nrf54l_05_10_15.dtsi:635 */
			clock: clock@10e000 {
				compatible = "nordic,nrf-clock"; /* in zephyr\dts\vendor\nordic\nrf54l_05_10_15.dtsi:636 */
				reg = < 0x10e000 0x1000 >;       /* in zephyr\dts\vendor\nordic\nrf54l_05_10_15.dtsi:637 */
				interrupts = < 0x105 0x1 >;      /* in zephyr\dts\vendor\nordic\nrf54l_05_10_15.dtsi:638 */
				status = "okay";                 /* in zephyr\boards\arm\xiao_nrf54l15\xiao_nrf54l15_nrf54l15_cpuapp.dts:176 */
			};

			/* node '/soc/peripheral@50000000/power@10e000' defined in zephyr\dts\vendor\nordic\nrf54l_05_10_15.dtsi:642 */
			power: power@10e000 {
				compatible = "nordic,nrf-power";  /* in zephyr\dts\vendor\nordic\nrf54l_05_10_15.dtsi:643 */
				reg = < 0x10e000 0x1000 >;        /* in zephyr\dts\vendor\nordic\nrf54l_05_10_15.dtsi:644 */
				ranges = < 0x0 0x10e000 0x1000 >; /* in zephyr\dts\vendor\nordic\nrf54l_05_10_15.dtsi:645 */
				interrupts = < 0x105 0x1 >;       /* in zephyr\dts\vendor\nordic\nrf54l_05_10_15.dtsi:646 */
				status = "disabled";              /* in zephyr\dts\vendor\nordic\nrf54l_05_10_15.dtsi:647 */
				#address-cells = < 0x1 >;         /* in zephyr\dts\vendor\nordic\nrf54l_05_10_15.dtsi:648 */
				#size-cells = < 0x1 >;            /* in zephyr\dts\vendor\nordic\nrf54l_05_10_15.dtsi:649 */

				/* node '/soc/peripheral@50000000/power@10e000/gpregret1@500' defined in zephyr\dts\vendor\nordic\nrf54l_05_10_15.dtsi:651 */
				gpregret1: gpregret1@500 {
					#address-cells = < 0x1 >;           /* in zephyr\dts\vendor\nordic\nrf54l_05_10_15.dtsi:652 */
					#size-cells = < 0x1 >;              /* in zephyr\dts\vendor\nordic\nrf54l_05_10_15.dtsi:653 */
					compatible = "nordic,nrf-gpregret"; /* in zephyr\dts\vendor\nordic\nrf54l_05_10_15.dtsi:654 */
					reg = < 0x500 0x1 >;                /* in zephyr\dts\vendor\nordic\nrf54l_05_10_15.dtsi:655 */
					status = "disabled";                /* in zephyr\dts\vendor\nordic\nrf54l_05_10_15.dtsi:656 */
				};

				/* node '/soc/peripheral@50000000/power@10e000/gpregret2@504' defined in zephyr\dts\vendor\nordic\nrf54l_05_10_15.dtsi:659 */
				gpregret2: gpregret2@504 {
					#address-cells = < 0x1 >;           /* in zephyr\dts\vendor\nordic\nrf54l_05_10_15.dtsi:660 */
					#size-cells = < 0x1 >;              /* in zephyr\dts\vendor\nordic\nrf54l_05_10_15.dtsi:661 */
					compatible = "nordic,nrf-gpregret"; /* in zephyr\dts\vendor\nordic\nrf54l_05_10_15.dtsi:662 */
					reg = < 0x504 0x1 >;                /* in zephyr\dts\vendor\nordic\nrf54l_05_10_15.dtsi:663 */
					status = "disabled";                /* in zephyr\dts\vendor\nordic\nrf54l_05_10_15.dtsi:664 */
				};
			};

			/* node '/soc/peripheral@50000000/comparator@106000' defined in zephyr\dts\vendor\nordic\nrf54l_05_10_15.dtsi:668 */
			comp: comparator@106000 {
				compatible = "nordic,nrf-comp"; /* in zephyr\dts\vendor\nordic\nrf54l_05_10_15.dtsi:673 */
				reg = < 0x106000 0x1000 >;      /* in zephyr\dts\vendor\nordic\nrf54l_05_10_15.dtsi:674 */
				status = "disabled";            /* in zephyr\dts\vendor\nordic\nrf54l_05_10_15.dtsi:675 */
				interrupts = < 0x106 0x1 >;     /* in zephyr\dts\vendor\nordic\nrf54l_05_10_15.dtsi:676 */
			};

			/* node '/soc/peripheral@50000000/watchdog@108000' defined in zephyr\dts\vendor\nordic\nrf54l_05_10_15.dtsi:682 */
			wdt30: watchdog@108000 {
				compatible = "nordic,nrf-wdt"; /* in zephyr\dts\vendor\nordic\nrf54l_05_10_15.dtsi:683 */
				reg = < 0x108000 0x620 >;      /* in zephyr\dts\vendor\nordic\nrf54l_05_10_15.dtsi:684 */
				interrupts = < 0x108 0x1 >;    /* in zephyr\dts\vendor\nordic\nrf54l_05_10_15.dtsi:685 */
				status = "disabled";           /* in zephyr\dts\vendor\nordic\nrf54l_05_10_15.dtsi:686 */
			};

			/* node '/soc/peripheral@50000000/watchdog@109000' defined in zephyr\dts\vendor\nordic\nrf54l_05_10_15.dtsi:690 */
			wdt31: watchdog@109000 {
				compatible = "nordic,nrf-wdt"; /* in zephyr\dts\vendor\nordic\nrf54l_05_10_15.dtsi:691 */
				reg = < 0x109000 0x620 >;      /* in zephyr\dts\vendor\nordic\nrf54l_05_10_15.dtsi:692 */
				interrupts = < 0x109 0x1 >;    /* in zephyr\dts\vendor\nordic\nrf54l_05_10_15.dtsi:693 */
				status = "disabled";           /* in zephyr\dts\vendor\nordic\nrf54l_05_10_15.dtsi:694 */
			};

			/* node '/soc/peripheral@50000000/gpio@10a000' defined in zephyr\dts\vendor\nordic\nrf54l_05_10_15.dtsi:697 */
			gpio0: gpio@10a000 {
				compatible = "nordic,nrf-gpio";  /* in zephyr\dts\vendor\nordic\nrf54l_05_10_15.dtsi:698 */
				gpio-controller;                 /* in zephyr\dts\vendor\nordic\nrf54l_05_10_15.dtsi:699 */
				reg = < 0x10a000 0x300 >;        /* in zephyr\dts\vendor\nordic\nrf54l_05_10_15.dtsi:700 */
				#gpio-cells = < 0x2 >;           /* in zephyr\dts\vendor\nordic\nrf54l_05_10_15.dtsi:701 */
				ngpios = < 0x5 >;                /* in zephyr\dts\vendor\nordic\nrf54l_05_10_15.dtsi:702 */
				status = "okay";                 /* in zephyr\boards\arm\xiao_nrf54l15\xiao_nrf54l15_nrf54l15_cpuapp.dts:112 */
				port = < 0x0 >;                  /* in zephyr\dts\vendor\nordic\nrf54l_05_10_15.dtsi:704 */
				gpiote-instance = < &gpiote30 >; /* in zephyr\dts\vendor\nordic\nrf54l_05_10_15.dtsi:705 */
				phandle = < 0x16 >;              /* in zephyr\boards\arm\xiao_nrf54l15\xiao_nrf54l15_nrf54l15_cpuapp.dts:92 */

				/* node '/soc/peripheral@50000000/gpio@10a000/imu_power_default_on' defined in zephyr\boards\arm\xiao_nrf54l15\xiao_nrf54l15_nrf54l15_cpuapp.dts:114 */
				imu_power_default_on: imu_power_default_on {
					gpio-hog;                       /* in zephyr\boards\arm\xiao_nrf54l15\xiao_nrf54l15_nrf54l15_cpuapp.dts:115 */
					gpios = < 0x1 0x0 >;            /* in zephyr\boards\arm\xiao_nrf54l15\xiao_nrf54l15_nrf54l15_cpuapp.dts:116 */
					line-name = "imu-power-enable"; /* in zephyr\boards\arm\xiao_nrf54l15\xiao_nrf54l15_nrf54l15_cpuapp.dts:117 */
				};
			};

			/* node '/soc/peripheral@50000000/gpiote@10c000' defined in zephyr\dts\vendor\nordic\nrf54l_05_10_15.dtsi:708 */
			gpiote30: gpiote@10c000 {
				compatible = "nordic,nrf-gpiote"; /* in zephyr\dts\vendor\nordic\nrf54l_05_10_15.dtsi:709 */
				reg = < 0x10c000 0x1000 >;        /* in zephyr\dts\vendor\nordic\nrf54l_05_10_15.dtsi:710 */
				status = "okay";                  /* in zephyr\boards\arm\xiao_nrf54l15\xiao_nrf54l15_nrf54l15_cpuapp.dts:134 */
				instance = < 0x1e >;              /* in zephyr\dts\vendor\nordic\nrf54l_05_10_15.dtsi:712 */
				interrupts = < 0x10d 0x1 >;       /* in zephyr\dts\arm\nordic\nrf54l_05_10_15_cpuapp.dtsi:91 */
				phandle = < 0x17 >;               /* in zephyr\dts\vendor\nordic\nrf54l_05_10_15.dtsi:705 */
			};

			/* node '/soc/peripheral@50000000/regulator@120000' defined in zephyr\dts\vendor\nordic\nrf54l_05_10_15.dtsi:715 */
			regulators: regulator@120000 {
				compatible = "nordic,nrf54l-regulators"; /* in zephyr\dts\vendor\nordic\nrf54l_05_10_15.dtsi:716 */
				reg = < 0x120000 0x1000 >;               /* in zephyr\dts\vendor\nordic\nrf54l_05_10_15.dtsi:717 */
				status = "okay";                         /* in zephyr\boards\arm\xiao_nrf54l15\xiao_nrf54l15_nrf54l15_cpuapp.dts:138 */
				#address-cells = < 0x1 >;                /* in zephyr\dts\vendor\nordic\nrf54l_05_10_15.dtsi:719 */
				#size-cells = < 0x1 >;                   /* in zephyr\dts\vendor\nordic\nrf54l_05_10_15.dtsi:720 */

				/* node '/soc/peripheral@50000000/regulator@120000/regulator@120600' defined in zephyr\dts\vendor\nordic\nrf54l_05_10_15.dtsi:722 */
				vregmain: regulator@120600 {
					compatible = "nordic,nrf5x-regulator"; /* in zephyr\dts\vendor\nordic\nrf54l_05_10_15.dtsi:723 */
					reg = < 0x120600 0x1 >;                /* in zephyr\dts\vendor\nordic\nrf54l_05_10_15.dtsi:724 */
					status = "okay";                       /* in zephyr\boards\arm\xiao_nrf54l15\xiao_nrf54l15_nrf54l15_cpuapp.dts:142 */
					regulator-name = "VREGMAIN";           /* in zephyr\dts\vendor\nordic\nrf54l_05_10_15.dtsi:726 */
					regulator-initial-mode = < 0x1 >;      /* in zephyr\boards\arm\xiao_nrf54l15\xiao_nrf54l15_nrf54l15_cpuapp.dts:143 */
				};
			};
		};

		/* node '/soc/rram-controller@5004b000' defined in zephyr\dts\vendor\nordic\nrf54l_05_10_15.dtsi:732 */
		rram_controller: rram-controller@5004b000 {
			compatible = "nordic,rram-controller"; /* in zephyr\dts\vendor\nordic\nrf54l_05_10_15.dtsi:733 */
			reg = < 0x5004b000 0x1000 >;           /* in zephyr\dts\vendor\nordic\nrf54l_05_10_15.dtsi:734 */
			#address-cells = < 0x1 >;              /* in zephyr\dts\vendor\nordic\nrf54l_05_10_15.dtsi:735 */
			#size-cells = < 0x1 >;                 /* in zephyr\dts\vendor\nordic\nrf54l_05_10_15.dtsi:736 */
			interrupts = < 0x4b 0x1 >;             /* in zephyr\dts\vendor\nordic\nrf54l_05_10_15.dtsi:737 */

			/* node '/soc/rram-controller@5004b000/rram@0' defined in zephyr\dts\vendor\nordic\nrf54l_05_10_15.dtsi:739 */
			cpuapp_rram: rram@0 {
				compatible = "soc-nv-flash";   /* in zephyr\dts\vendor\nordic\nrf54l_05_10_15.dtsi:740 */
				erase-block-size = < 0x1000 >; /* in zephyr\dts\vendor\nordic\nrf54l_05_10_15.dtsi:741 */
				write-block-size = < 0x10 >;   /* in zephyr\dts\vendor\nordic\nrf54l_05_10_15.dtsi:742 */
				reg = < 0x0 0x165000 >;        /* in zephyr\dts\vendor\nordic\nrf54l15.dtsi:28 */

				/* node '/soc/rram-controller@5004b000/rram@0/partitions' defined in zephyr\boards\arm\xiao_nrf54l15\xiao_nrf54l15_nrf54l15_cpuapp.dts:181 */
				partitions {
					compatible = "fixed-partitions"; /* in zephyr\boards\arm\xiao_nrf54l15\xiao_nrf54l15_nrf54l15_cpuapp.dts:182 */
					#address-cells = < 0x1 >;        /* in zephyr\boards\arm\xiao_nrf54l15\xiao_nrf54l15_nrf54l15_cpuapp.dts:183 */
					#size-cells = < 0x1 >;           /* in zephyr\boards\arm\xiao_nrf54l15\xiao_nrf54l15_nrf54l15_cpuapp.dts:184 */

					/* node '/soc/rram-controller@5004b000/rram@0/partitions/partition@0' defined in zephyr\boards\arm\xiao_nrf54l15\xiao_nrf54l15_nrf54l15_cpuapp.dts:186 */
					boot_partition: partition@0 {
						label = "mcuboot";     /* in zephyr\boards\arm\xiao_nrf54l15\xiao_nrf54l15_nrf54l15_cpuapp.dts:187 */
						reg = < 0x0 0x10000 >; /* in zephyr\boards\arm\xiao_nrf54l15\xiao_nrf54l15_nrf54l15_cpuapp.dts:188 */
					};

					/* node '/soc/rram-controller@5004b000/rram@0/partitions/partition@10000' defined in zephyr\boards\arm\xiao_nrf54l15\xiao_nrf54l15_nrf54l15_cpuapp.dts:191 */
					slot0_partition: partition@10000 {
						label = "image-0";         /* in zephyr\boards\arm\xiao_nrf54l15\xiao_nrf54l15_nrf54l15_cpuapp.dts:192 */
						reg = < 0x10000 0xa6000 >; /* in zephyr\boards\arm\xiao_nrf54l15\xiao_nrf54l15_nrf54l15_cpuapp.dts:193 */
					};

					/* node '/soc/rram-controller@5004b000/rram@0/partitions/partition@b6000' defined in zephyr\boards\arm\xiao_nrf54l15\xiao_nrf54l15_nrf54l15_cpuapp.dts:196 */
					slot1_partition: partition@b6000 {
						label = "image-1";         /* in zephyr\boards\arm\xiao_nrf54l15\xiao_nrf54l15_nrf54l15_cpuapp.dts:197 */
						reg = < 0xb6000 0xa6000 >; /* in zephyr\boards\arm\xiao_nrf54l15\xiao_nrf54l15_nrf54l15_cpuapp.dts:198 */
					};

					/* node '/soc/rram-controller@5004b000/rram@0/partitions/partition@15c000' defined in zephyr\boards\arm\xiao_nrf54l15\xiao_nrf54l15_nrf54l15_cpuapp.dts:201 */
					storage_partition: partition@15c000 {
						label = "storage";         /* in zephyr\boards\arm\xiao_nrf54l15\xiao_nrf54l15_nrf54l15_cpuapp.dts:202 */
						reg = < 0x15c000 0x9000 >; /* in zephyr\boards\arm\xiao_nrf54l15\xiao_nrf54l15_nrf54l15_cpuapp.dts:203 */
					};
				};
			};
		};

		/* node '/soc/memory@50041000' defined in zephyr\dts\vendor\nordic\nrf54l_05_10_15.dtsi:746 */
		nrf_mpc: memory@50041000 {
			compatible = "nordic,nrf-mpc";     /* in zephyr\dts\vendor\nordic\nrf54l_05_10_15.dtsi:747 */
			reg = < 0x50041000 0x1000 >;       /* in zephyr\dts\vendor\nordic\nrf54l_05_10_15.dtsi:748 */
			#address-cells = < 0x1 >;          /* in zephyr\dts\vendor\nordic\nrf54l_05_10_15.dtsi:749 */
			#size-cells = < 0x1 >;             /* in zephyr\dts\vendor\nordic\nrf54l_05_10_15.dtsi:750 */
			override-num = < 0x5 >;            /* in zephyr\dts\vendor\nordic\nrf54l_05_10_15.dtsi:751 */
			override-granularity = < 0x1000 >; /* in zephyr\dts\vendor\nordic\nrf54l_05_10_15.dtsi:752 */
		};

		/* node '/soc/cpuapp-ppb-bus' defined in zephyr\dts\vendor\nordic\nrf54l_05_10_15.dtsi:755 */
		cpuapp_ppb: cpuapp-ppb-bus {
			#address-cells = < 0x1 >;  /* in zephyr\dts\vendor\nordic\nrf54l_05_10_15.dtsi:756 */
			#size-cells = < 0x1 >;     /* in zephyr\dts\vendor\nordic\nrf54l_05_10_15.dtsi:757 */
			compatible = "simple-bus"; /* in zephyr\dts\arm\nordic\nrf54l_05_10_15_cpuapp.dtsi:66 */
			ranges;                    /* in zephyr\dts\arm\nordic\nrf54l_05_10_15_cpuapp.dtsi:67 */

			/* node '/soc/cpuapp-ppb-bus/interrupt-controller@e000e100' defined in zephyr\dts\vendor\nordic\nrf54l_05_10_15.dtsi:759 */
			cpuapp_nvic: nvic: interrupt-controller@e000e100 {
				#address-cells = < 0x1 >;            /* in zephyr\dts\vendor\nordic\nrf54l_05_10_15.dtsi:760 */
				compatible = "arm,v8m-nvic";         /* in zephyr\dts\vendor\nordic\nrf54l_05_10_15.dtsi:761 */
				reg = < 0xe000e100 0xc00 >;          /* in zephyr\dts\vendor\nordic\nrf54l_05_10_15.dtsi:762 */
				arm,num-irq-priority-bits = < 0x3 >; /* in zephyr\dts\vendor\nordic\nrf54l_05_10_15.dtsi:763 */
				interrupt-controller;                /* in zephyr\dts\vendor\nordic\nrf54l_05_10_15.dtsi:764 */
				#interrupt-cells = < 0x2 >;          /* in zephyr\dts\vendor\nordic\nrf54l_05_10_15.dtsi:765 */
				phandle = < 0x2 >;                   /* in zephyr\dts\arm\nordic\nrf54l_05_10_15_cpuapp.dtsi:24 */
			};

			/* node '/soc/cpuapp-ppb-bus/timer@e000e010' defined in zephyr\dts\vendor\nordic\nrf54l_05_10_15.dtsi:768 */
			cpuapp_systick: systick: timer@e000e010 {
				compatible = "arm,armv8m-systick"; /* in zephyr\dts\vendor\nordic\nrf54l_05_10_15.dtsi:769 */
				reg = < 0xe000e010 0x10 >;         /* in zephyr\dts\vendor\nordic\nrf54l_05_10_15.dtsi:770 */
				status = "disabled";               /* in zephyr\dts\vendor\nordic\nrf54l_05_10_15.dtsi:771 */
			};
		};
	};

	/* node '/chosen' defined in zephyr\dts\arm\nordic\nrf54l_05_10_15_cpuapp.dtsi:17 */
	chosen {
		zephyr,bt-hci = &bt_hci_sdc;                 /* in zephyr\dts\arm\nordic\nrf54l_05_10_15_cpuapp.dtsi:18 */
		zephyr,entropy = &psa_rng;                   /* in zephyr\dts\arm\nordic\nrf54l_05_10_15_cpuapp.dtsi:19 */
		zephyr,code-partition = &slot0_partition;    /* in zephyr\boards\arm\xiao_nrf54l15\xiao_nrf54l15_nrf54l15_cpuapp.dts:44 */
		zephyr,sram = &cpuapp_sram;                  /* in zephyr\boards\arm\xiao_nrf54l15\xiao_nrf54l15_nrf54l15_cpuapp.dts:45 */
		zephyr,flash = &cpuapp_rram;                 /* in zephyr\boards\arm\xiao_nrf54l15\xiao_nrf54l15_nrf54l15_cpuapp.dts:46 */
		zephyr,flash-controller = &rram_controller;  /* in zephyr\boards\arm\xiao_nrf54l15\xiao_nrf54l15_nrf54l15_cpuapp.dts:47 */
		zephyr,console = &uart20;                    /* in zephyr\boards\arm\xiao_nrf54l15\xiao_nrf54l15_nrf54l15_cpuapp.dts:48 */
		zephyr,shell-uart = &uart20;                 /* in zephyr\boards\arm\xiao_nrf54l15\xiao_nrf54l15_nrf54l15_cpuapp.dts:49 */
		nordic,rpc-uart = &uart20;                   /* in zephyr\boards\arm\xiao_nrf54l15\xiao_nrf54l15_nrf54l15_cpuapp.dts:50 */
		zephyr,ieee802154 = &ieee802154;             /* in zephyr\boards\arm\xiao_nrf54l15\xiao_nrf54l15_nrf54l15_cpuapp.dts:51 */
		zephyr,display = &gc9a01_xiao_round_display; /* in zephyr\boards\shields\seeed_xiao_round_display\seeed_xiao_round_display.overlay:12 */
		zephyr,touch = &chsc6x_xiao_round_display;   /* in zephyr\boards\shields\seeed_xiao_round_display\seeed_xiao_round_display.overlay:13 */
	};

	/* node '/rng' defined in zephyr\dts\arm\nordic\nrf54l_05_10_15_cpuapp.dtsi:28 */
	rng: rng {
		status = "okay";                          /* in zephyr\dts\arm\nordic\nrf54l_05_10_15_cpuapp.dtsi:29 */
		compatible = "nordic,nrf-cracen-ctrdrbg"; /* in zephyr\dts\arm\nordic\nrf54l_05_10_15_cpuapp.dtsi:30 */
	};

	/* node '/psa-rng' defined in zephyr\dts\arm\nordic\nrf54l_05_10_15_cpuapp.dtsi:33 */
	psa_rng: psa-rng {
		compatible = "zephyr,psa-crypto-rng"; /* in zephyr\dts\arm\nordic\nrf54l_05_10_15_cpuapp.dtsi:34 */
		status = "okay";                      /* in zephyr\dts\arm\nordic\nrf54l_05_10_15_cpuapp.dtsi:35 */
	};

	/* node '/connector' defined in zephyr\boards\arm\xiao_nrf54l15\seeed_xiao_connector.dtsi:6 */
	xiao_d: connector {
		compatible = "seeed,xiao-gpio";            /* in zephyr\boards\arm\xiao_nrf54l15\seeed_xiao_connector.dtsi:7 */
		#gpio-cells = < 0x2 >;                     /* in zephyr\boards\arm\xiao_nrf54l15\seeed_xiao_connector.dtsi:8 */
		gpio-map-mask = < 0xffffffff 0xffffffc0 >; /* in zephyr\boards\arm\xiao_nrf54l15\seeed_xiao_connector.dtsi:9 */
		gpio-map-pass-thru = < 0x0 0x3f >;         /* in zephyr\boards\arm\xiao_nrf54l15\seeed_xiao_connector.dtsi:10 */
		gpio-map = < 0x0 0x0 &gpio1 0x4 0x0 >,
		           < 0x1 0x0 &gpio1 0x5 0x0 >,
		           < 0x2 0x0 &gpio1 0x6 0x0 >,
		           < 0x3 0x0 &gpio1 0x7 0x0 >,
		           < 0x4 0x0 &gpio1 0xa 0x0 >,
		           < 0x5 0x0 &gpio1 0xb 0x0 >,
		           < 0x6 0x0 &gpio2 0x8 0x0 >,
		           < 0x7 0x0 &gpio2 0x7 0x0 >,
		           < 0x8 0x0 &gpio2 0x1 0x0 >,
		           < 0x9 0x0 &gpio2 0x4 0x0 >,
		           < 0xa 0x0 &gpio2 0x2 0x0 >;     /* in zephyr\boards\arm\xiao_nrf54l15\seeed_xiao_connector.dtsi:11 */
		phandle = < 0x5 >;                         /* in zephyr\boards\shields\seeed_xiao_round_display\seeed_xiao_round_display.overlay:84 */
	};

	/* node '/leds' defined in zephyr\boards\arm\xiao_nrf54l15\xiao_nrf54l15_common.dtsi:9 */
	leds {
		compatible = "gpio-leds"; /* in zephyr\boards\arm\xiao_nrf54l15\xiao_nrf54l15_common.dtsi:10 */

		/* node '/leds/led_0' defined in zephyr\boards\arm\xiao_nrf54l15\xiao_nrf54l15_common.dtsi:12 */
		led0: led_0 {
			gpios = < &gpio2 0x0 0x0 >; /* in zephyr\boards\arm\xiao_nrf54l15\xiao_nrf54l15_common.dtsi:13 */
			label = "LED 0";            /* in zephyr\boards\arm\xiao_nrf54l15\xiao_nrf54l15_common.dtsi:14 */
		};
	};

	/* node '/buttons' defined in zephyr\boards\arm\xiao_nrf54l15\xiao_nrf54l15_common.dtsi:18 */
	buttons: buttons {
		compatible = "gpio-keys"; /* in zephyr\boards\arm\xiao_nrf54l15\xiao_nrf54l15_common.dtsi:19 */

		/* node '/buttons/usr-btn' defined in zephyr\boards\arm\xiao_nrf54l15\xiao_nrf54l15_common.dtsi:21 */
		usr_btn: usr-btn {
			gpios = < &gpio0 0x0 0x11 >; /* in zephyr\boards\arm\xiao_nrf54l15\xiao_nrf54l15_common.dtsi:22 */
			label = "USR";               /* in zephyr\boards\arm\xiao_nrf54l15\xiao_nrf54l15_common.dtsi:23 */
			zephyr,code = < 0x1c >;      /* in zephyr\boards\arm\xiao_nrf54l15\xiao_nrf54l15_common.dtsi:24 */
		};
	};

	/* node '/aliases' defined in zephyr\boards\arm\xiao_nrf54l15\xiao_nrf54l15_common.dtsi:28 */
	aliases {
		led0 = &led0;                      /* in zephyr\boards\arm\xiao_nrf54l15\xiao_nrf54l15_common.dtsi:29 */
		buttons = &buttons;                /* in zephyr\boards\arm\xiao_nrf54l15\xiao_nrf54l15_common.dtsi:30 */
		dmic20 = &pdm20;                   /* in zephyr\boards\arm\xiao_nrf54l15\xiao_nrf54l15_common.dtsi:31 */
		sw0 = &usr_btn;                    /* in zephyr\boards\arm\xiao_nrf54l15\xiao_nrf54l15_common.dtsi:32 */
		watchdog0 = &wdt31;                /* in zephyr\boards\arm\xiao_nrf54l15\xiao_nrf54l15_common.dtsi:33 */
		imu0 = &lsm6dso;                   /* in zephyr\boards\arm\xiao_nrf54l15\xiao_nrf54l15_nrf54l15_cpuapp.dts:55 */
		rtc = &pcf8563_xiao_round_display; /* in zephyr\boards\shields\seeed_xiao_round_display\seeed_xiao_round_display.overlay:29 */
	};

	/* node '/pdm-imu-pwr' defined in zephyr\boards\arm\xiao_nrf54l15\xiao_nrf54l15_nrf54l15_cpuapp.dts:14 */
	pdm_imu_pwr: pdm-imu-pwr {
		compatible = "regulator-fixed";    /* in zephyr\boards\arm\xiao_nrf54l15\xiao_nrf54l15_nrf54l15_cpuapp.dts:15 */
		regulator-name = "pdm-imu-pwr";    /* in zephyr\boards\arm\xiao_nrf54l15\xiao_nrf54l15_nrf54l15_cpuapp.dts:16 */
		enable-gpios = < &gpio0 0x1 0x0 >; /* in zephyr\boards\arm\xiao_nrf54l15\xiao_nrf54l15_nrf54l15_cpuapp.dts:17 */
		regulator-boot-on;                 /* in zephyr\boards\arm\xiao_nrf54l15\xiao_nrf54l15_nrf54l15_cpuapp.dts:18 */
		startup-delay-us = < 0x1388 >;     /* in zephyr\boards\arm\xiao_nrf54l15\xiao_nrf54l15_nrf54l15_cpuapp.dts:19 */
	};

	/* node '/rfsw-ctl' defined in zephyr\boards\arm\xiao_nrf54l15\xiao_nrf54l15_nrf54l15_cpuapp.dts:22 */
	rfsw_ctl: rfsw-ctl {
		compatible = "regulator-fixed";    /* in zephyr\boards\arm\xiao_nrf54l15\xiao_nrf54l15_nrf54l15_cpuapp.dts:23 */
		regulator-name = "rfsw-ctl";       /* in zephyr\boards\arm\xiao_nrf54l15\xiao_nrf54l15_nrf54l15_cpuapp.dts:24 */
		enable-gpios = < &gpio2 0x5 0x1 >; /* in zephyr\boards\arm\xiao_nrf54l15\xiao_nrf54l15_nrf54l15_cpuapp.dts:25 */
		regulator-boot-on;                 /* in zephyr\boards\arm\xiao_nrf54l15\xiao_nrf54l15_nrf54l15_cpuapp.dts:26 */
	};

	/* node '/rfsw-pwr' defined in zephyr\boards\arm\xiao_nrf54l15\xiao_nrf54l15_nrf54l15_cpuapp.dts:29 */
	rfsw_pwr: rfsw-pwr {
		compatible = "regulator-fixed";    /* in zephyr\boards\arm\xiao_nrf54l15\xiao_nrf54l15_nrf54l15_cpuapp.dts:30 */
		regulator-name = "rfsw-pwr";       /* in zephyr\boards\arm\xiao_nrf54l15\xiao_nrf54l15_nrf54l15_cpuapp.dts:31 */
		enable-gpios = < &gpio2 0x3 0x0 >; /* in zephyr\boards\arm\xiao_nrf54l15\xiao_nrf54l15_nrf54l15_cpuapp.dts:32 */
		regulator-boot-on;                 /* in zephyr\boards\arm\xiao_nrf54l15\xiao_nrf54l15_nrf54l15_cpuapp.dts:33 */
	};

	/* node '/vbat-pwr' defined in zephyr\boards\arm\xiao_nrf54l15\xiao_nrf54l15_nrf54l15_cpuapp.dts:36 */
	vbat_pwr: vbat-pwr {
		compatible = "regulator-fixed";    /* in zephyr\boards\arm\xiao_nrf54l15\xiao_nrf54l15_nrf54l15_cpuapp.dts:37 */
		regulator-name = "vbat";           /* in zephyr\boards\arm\xiao_nrf54l15\xiao_nrf54l15_nrf54l15_cpuapp.dts:38 */
		enable-gpios = < &gpio1 0xf 0x0 >; /* in zephyr\boards\arm\xiao_nrf54l15\xiao_nrf54l15_nrf54l15_cpuapp.dts:39 */
		regulator-boot-on;                 /* in zephyr\boards\arm\xiao_nrf54l15\xiao_nrf54l15_nrf54l15_cpuapp.dts:40 */
	};

	/* node '/vbatt' defined in zephyr\boards\shields\seeed_xiao_round_display\seeed_xiao_round_display.overlay:16 */
	vbatt {
		compatible = "voltage-divider";  /* in zephyr\boards\shields\seeed_xiao_round_display\seeed_xiao_round_display.overlay:17 */
		io-channels = < &xiao_adc 0x0 >; /* in zephyr\boards\shields\seeed_xiao_round_display\seeed_xiao_round_display.overlay:18 */
		output-ohms = < 0x72bf0 >;       /* in zephyr\boards\shields\seeed_xiao_round_display\seeed_xiao_round_display.overlay:19 */
		full-ohms = < 0xe57e0 >;         /* in zephyr\boards\shields\seeed_xiao_round_display\seeed_xiao_round_display.overlay:20 */
	};

	/* node '/lvgl_pointer' defined in zephyr\boards\shields\seeed_xiao_round_display\seeed_xiao_round_display.overlay:23 */
	lvgl_pointer {
		compatible = "zephyr,lvgl-pointer-input"; /* in zephyr\boards\shields\seeed_xiao_round_display\seeed_xiao_round_display.overlay:24 */
		input = < &chsc6x_xiao_round_display >;   /* in zephyr\boards\shields\seeed_xiao_round_display\seeed_xiao_round_display.overlay:25 */
	};

	/* node '/xiao_round_display_mipi_dbi' defined in zephyr\boards\shields\seeed_xiao_round_display\seeed_xiao_round_display.overlay:32 */
	xiao_round_display_mipi_dbi {
		compatible = "zephyr,mipi-dbi-spi"; /* in zephyr\boards\shields\seeed_xiao_round_display\seeed_xiao_round_display.overlay:33 */
		spi-dev = < &xiao_spi >;            /* in zephyr\boards\shields\seeed_xiao_round_display\seeed_xiao_round_display.overlay:34 */
		dc-gpios = < &xiao_d 0x3 0x0 >;     /* in zephyr\boards\shields\seeed_xiao_round_display\seeed_xiao_round_display.overlay:35 */
		write-only;                         /* in zephyr\boards\shields\seeed_xiao_round_display\seeed_xiao_round_display.overlay:36 */
		#address-cells = < 0x1 >;           /* in zephyr\boards\shields\seeed_xiao_round_display\seeed_xiao_round_display.overlay:37 */
		#size-cells = < 0x0 >;              /* in zephyr\boards\shields\seeed_xiao_round_display\seeed_xiao_round_display.overlay:38 */

		/* node '/xiao_round_display_mipi_dbi/gc9a01@0' defined in zephyr\boards\shields\seeed_xiao_round_display\seeed_xiao_round_display.overlay:40 */
		gc9a01_xiao_round_display: gc9a01@0 {
			status = "okay";                    /* in zephyr\boards\shields\seeed_xiao_round_display\seeed_xiao_round_display.overlay:41 */
			compatible = "galaxycore,gc9x01x";  /* in zephyr\boards\shields\seeed_xiao_round_display\seeed_xiao_round_display.overlay:42 */
			reg = < 0x0 >;                      /* in zephyr\boards\shields\seeed_xiao_round_display\seeed_xiao_round_display.overlay:43 */
			mipi-max-frequency = < 0x5f5e100 >; /* in zephyr\boards\shields\seeed_xiao_round_display\seeed_xiao_round_display.overlay:44 */
			pixel-format = < 0x10 >;            /* in zephyr\boards\shields\seeed_xiao_round_display\seeed_xiao_round_display.overlay:45 */
			width = < 0xf0 >;                   /* in zephyr\boards\shields\seeed_xiao_round_display\seeed_xiao_round_display.overlay:46 */
			height = < 0xf0 >;                  /* in zephyr\boards\shields\seeed_xiao_round_display\seeed_xiao_round_display.overlay:47 */
			display-inversion;                  /* in zephyr\boards\shields\seeed_xiao_round_display\seeed_xiao_round_display.overlay:48 */
		};
	};
};
